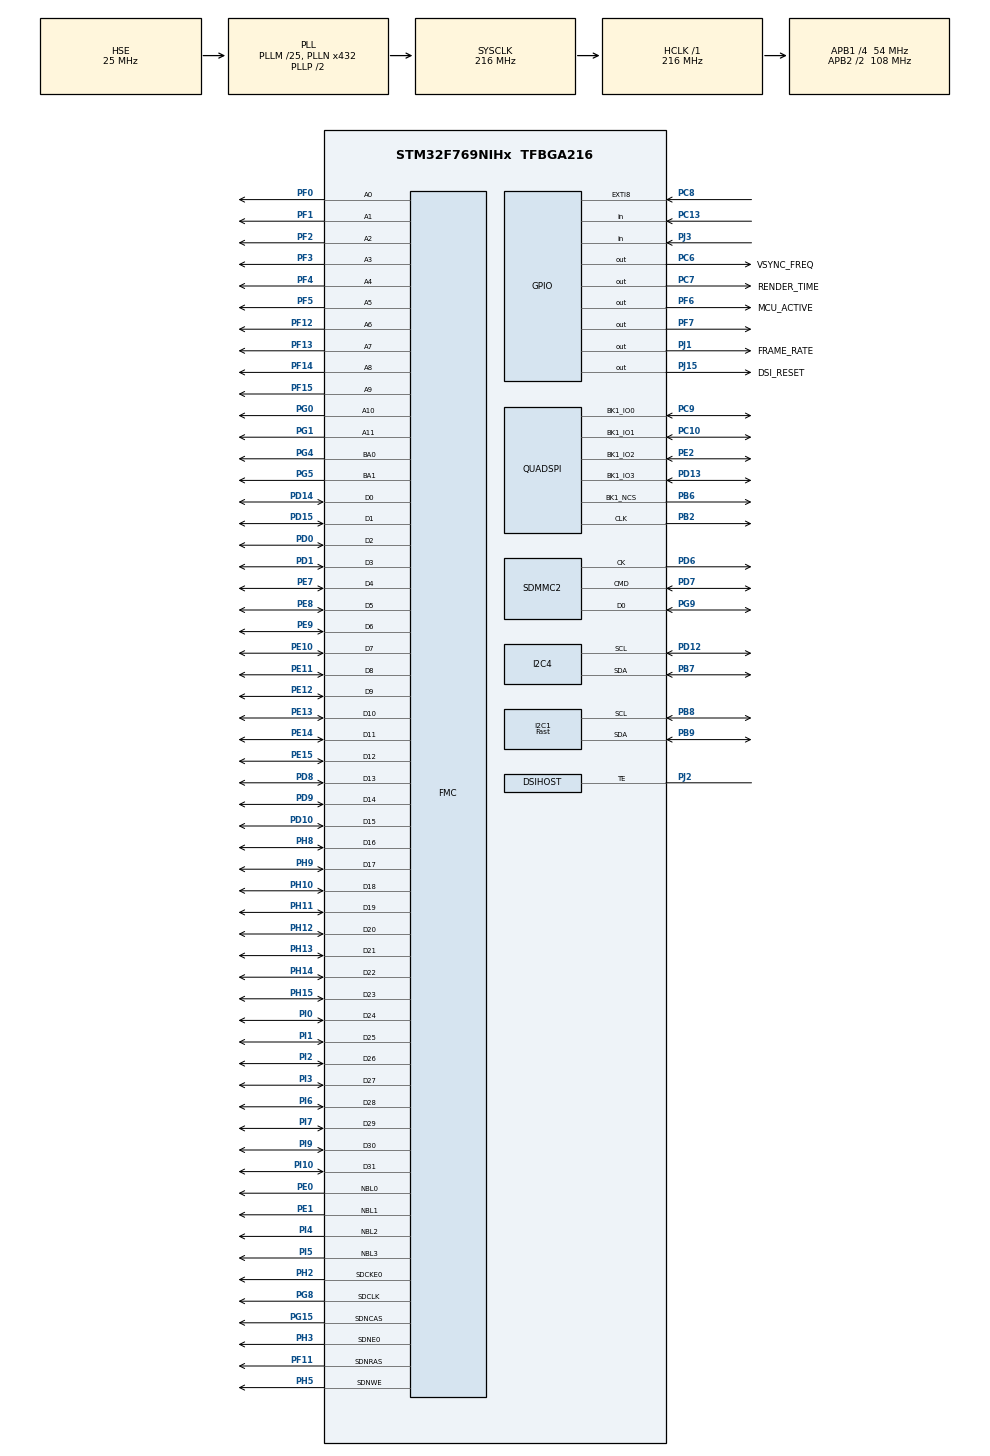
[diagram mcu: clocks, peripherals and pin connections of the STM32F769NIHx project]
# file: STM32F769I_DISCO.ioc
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CORTEX_M7.ART_ACCLERATOR_ENABLE=1
CORTEX_M7.AccessPermission-Cortex_Memory_Protection_Unit_Region0_Settings=MPU_REGION_FULL_ACCESS
CORTEX_M7.AccessPermission-Cortex_Memory_Protection_Unit_Region1_Settings=MPU_REGION_NO_ACCESS
CORTEX_M7.AccessPermission-Cortex_Memory_Protection_Unit_Region2_Settings=MPU_REGION_FULL_ACCESS
CORTEX_M7.AccessPermission-Cortex_Memory_Protection_Unit_Region3_Settings=MPU_REGION_NO_ACCESS
CORTEX_M7.AccessPermission-Cortex_Memory_Protection_Unit_Region4_Settings=MPU_REGION_FULL_ACCESS
CORTEX_M7.BaseAddress-Cortex_Memory_Protection_Unit_Region0_Settings=0x20000000
CORTEX_M7.BaseAddress-Cortex_Memory_Protection_Unit_Region1_Settings=0x90000000
CORTEX_M7.BaseAddress-Cortex_Memory_Protection_Unit_Region2_Settings=0x90000000
CORTEX_M7.BaseAddress-Cortex_Memory_Protection_Unit_Region3_Settings=0xC0000000
CORTEX_M7.BaseAddress-Cortex_Memory_Protection_Unit_Region4_Settings=0xC0000000
CORTEX_M7.CPU_DCache=Enabled
CORTEX_M7.CPU_ICache=Disabled
CORTEX_M7.DisableExec-Cortex_Memory_Protection_Unit_Region0_Settings=MPU_INSTRUCTION_ACCESS_DISABLE
CORTEX_M7.DisableExec-Cortex_Memory_Protection_Unit_Region1_Settings=MPU_INSTRUCTION_ACCESS_DISABLE
CORTEX_M7.DisableExec-Cortex_Memory_Protection_Unit_Region2_Settings=MPU_INSTRUCTION_ACCESS_DISABLE
CORTEX_M7.DisableExec-Cortex_Memory_Protection_Unit_Region3_Settings=MPU_INSTRUCTION_ACCESS_DISABLE
CORTEX_M7.DisableExec-Cortex_Memory_Protection_Unit_Region4_Settings=MPU_INSTRUCTION_ACCESS_DISABLE
CORTEX_M7.Enable-Cortex_Memory_Protection_Unit_Region0_Settings=MPU_REGION_ENABLE
CORTEX_M7.Enable-Cortex_Memory_Protection_Unit_Region1_Settings=MPU_REGION_ENABLE
CORTEX_M7.Enable-Cortex_Memory_Protection_Unit_Region2_Settings=MPU_REGION_ENABLE
CORTEX_M7.Enable-Cortex_Memory_Protection_Unit_Region3_Settings=MPU_REGION_ENABLE
CORTEX_M7.Enable-Cortex_Memory_Protection_Unit_Region4_Settings=MPU_REGION_ENABLE
CORTEX_M7.IsBufferable-Cortex_Memory_Protection_Unit_Region0_Settings=MPU_ACCESS_BUFFERABLE
CORTEX_M7.IsBufferable-Cortex_Memory_Protection_Unit_Region2_Settings=MPU_ACCESS_BUFFERABLE
CORTEX_M7.IsBufferable-Cortex_Memory_Protection_Unit_Region3_Settings=MPU_ACCESS_NOT_BUFFERABLE
CORTEX_M7.IsBufferable-Cortex_Memory_Protection_Unit_Region4_Settings=MPU_ACCESS_BUFFERABLE
CORTEX_M7.IsCacheable-Cortex_Memory_Protection_Unit_Region0_Settings=MPU_ACCESS_CACHEABLE
CORTEX_M7.IsCacheable-Cortex_Memory_Protection_Unit_Region2_Settings=MPU_ACCESS_CACHEABLE
CORTEX_M7.IsCacheable-Cortex_Memory_Protection_Unit_Region3_Settings=MPU_ACCESS_NOT_CACHEABLE
CORTEX_M7.IsCacheable-Cortex_Memory_Protection_Unit_Region4_Settings=MPU_ACCESS_CACHEABLE
CORTEX_M7.IsShareable-Cortex_Memory_Protection_Unit_Region0_Settings=MPU_ACCESS_NOT_SHAREABLE
CORTEX_M7.IsShareable-Cortex_Memory_Protection_Unit_Region2_Settings=MPU_ACCESS_NOT_SHAREABLE
CORTEX_M7.MPU_Control=MPU_PRIVILEGED_DEFAULT
CORTEX_M7.PREFETCH_ENABLE=0
CORTEX_M7.Size-Cortex_Memory_Protection_Unit_Region0_Settings=MPU_REGION_SIZE_512KB
CORTEX_M7.Size-Cortex_Memory_Protection_Unit_Region1_Settings=MPU_REGION_SIZE_512MB
CORTEX_M7.Size-Cortex_Memory_Protection_Unit_Region2_Settings=MPU_REGION_SIZE_64MB
CORTEX_M7.Size-Cortex_Memory_Protection_Unit_Region3_Settings=MPU_REGION_SIZE_512MB
CORTEX_M7.Size-Cortex_Memory_Protection_Unit_Region4_Settings=MPU_REGION_SIZE_16MB
DMA2D.ColorMode=DMA2D_OUTPUT_ARGB8888
DMA2D.Mode=DMA2D_M2M
DSIHOST.AcknowledgeRequest=DSI_ACKNOWLEDGE_ENABLE
DSIHOST.AutomaticRefresh=DSI_AR_DISABLE
DSIHOST.BTA_FlowControl=DSI_FLOW_CONTROL_BTA
DSIHOST.CommandSize=200
DSIHOST.LPDcsLongWrite=DSI_LP_DLW_ENABLE
DSIHOST.LPDcsShortReadNoP=DSI_LP_DSR0P_ENABLE
DSIHOST.LPDcsShortWriteNoP=DSI_LP_DSW0P_ENABLE
DSIHOST.LPDcsShortWriteOneP=DSI_LP_DSW1P_ENABLE
DSIHOST.LPGenLongWrite=DSI_LP_GLW_ENABLE
DSIHOST.LPGenShortReadNoP=DSI_LP_GSR0P_ENABLE
DSIHOST.LPGenShortReadOneP=DSI_LP_GSR1P_ENABLE
DSIHOST.LPGenShortReadTwoP=DSI_LP_GSR2P_ENABLE
DSIHOST.LPGenShortWriteNoP=DSI_LP_GSW0P_ENABLE
DSIHOST.LPGenShortWriteOneP=DSI_LP_GSW1P_ENABLE
DSIHOST.LPGenShortWriteTwoP=DSI_LP_GSW2P_ENABLE
DSIHOST.LPMaxReadPacket=DSI_LP_MRDP_ENABLE
DSIHOST.LPWREIE=HAL_DSI_ERROR_OVF
DSIHOST.NumberOfLanes=DSI_TWO_DATA_LANES
DSIHOST.TEAcknowledgeRequest=DSI_TE_ACKNOWLEDGE_ENABLE
DSIHOST_CKN.Mode=DSIHost_Adapted_TE
DSIHOST_CKN.Signal=DSIHOST_CKN
DSIHOST_CKP.Mode=DSIHost_Adapted_TE
DSIHOST_CKP.Signal=DSIHOST_CKP
DSIHOST_D0N.Mode=DSIHost_Adapted_TE
DSIHOST_D0N.Signal=DSIHOST_D0N
DSIHOST_D0P.Mode=DSIHost_Adapted_TE
DSIHOST_D0P.Signal=DSIHOST_D0P
DSIHOST_D1N.Mode=DSIHost_Adapted_TE
DSIHOST_D1N.Signal=DSIHOST_D1N
DSIHOST_D1P.Mode=DSIHost_Adapted_TE
DSIHOST_D1P.Signal=DSIHOST_D1P
Dma.Request0=SDMMC2_RX
Dma.Request1=SDMMC2_TX
Dma.SDMMC2_RX.0.Direction=DMA_PERIPH_TO_MEMORY
Dma.SDMMC2_RX.0.FIFOMode=DMA_FIFOMODE_ENABLE
Dma.SDMMC2_RX.0.FIFOThreshold=DMA_FIFO_THRESHOLD_FULL
Dma.SDMMC2_RX.0.Instance=DMA2_Stream0
Dma.SDMMC2_RX.0.MemBurst=DMA_MBURST_INC4
Dma.SDMMC2_RX.0.MemDataAlignment=DMA_MDATAALIGN_WORD
Dma.SDMMC2_RX.0.MemInc=DMA_MINC_ENABLE
Dma.SDMMC2_RX.0.Mode=DMA_PFCTRL
Dma.SDMMC2_RX.0.PeriphBurst=DMA_PBURST_INC4
Dma.SDMMC2_RX.0.PeriphDataAlignment=DMA_PDATAALIGN_WORD
Dma.SDMMC2_RX.0.PeriphInc=DMA_PINC_DISABLE
Dma.SDMMC2_RX.0.Priority=DMA_PRIORITY_LOW
Dma.SDMMC2_TX.1.Direction=DMA_MEMORY_TO_PERIPH
Dma.SDMMC2_TX.1.FIFOMode=DMA_FIFOMODE_ENABLE
Dma.SDMMC2_TX.1.FIFOThreshold=DMA_FIFO_THRESHOLD_FULL
Dma.SDMMC2_TX.1.Instance=DMA2_Stream5
Dma.SDMMC2_TX.1.MemBurst=DMA_MBURST_INC4
Dma.SDMMC2_TX.1.MemDataAlignment=DMA_MDATAALIGN_WORD
Dma.SDMMC2_TX.1.MemInc=DMA_MINC_ENABLE
Dma.SDMMC2_TX.1.Mode=DMA_PFCTRL
Dma.SDMMC2_TX.1.PeriphBurst=DMA_PBURST_INC4
Dma.SDMMC2_TX.1.PeriphDataAlignment=DMA_PDATAALIGN_WORD
Dma.SDMMC2_TX.1.PeriphInc=DMA_PINC_DISABLE
Dma.SDMMC2_TX.1.Priority=DMA_PRIORITY_LOW
FATFS.BSP.number=1
FATFS._FS_EXFAT=1
FATFS._MAX_SS=4096
FATFS._USE_LFN=2
FATFS0.BSP.STBoard=false
FATFS0.BSP.api=Unknown
FATFS0.BSP.instance=PC13
FATFS0.BSP.ip=GPIO
FATFS0.BSP.mode=Input
FATFS0.BSP.name=Detect_SDIO
FATFS0.BSP.solution=PC13
FMC.CASLatency1=FMC_SDRAM_CAS_LATENCY_3
FMC.ExitSelfRefreshDelay1=7
FMC.LoadToActiveDelay1=2
FMC.RCDDelay1=3
FMC.RPDelay1=2
FMC.ReadBurst1=FMC_SDRAM_RBURST_ENABLE
FMC.RowCycleDelay1=7
FMC.SDClockPeriod1=FMC_SDRAM_CLOCK_PERIOD_2
FMC.SelfRefreshTime1=4
FMC.WriteRecoveryTime1=2
FREERTOS.Queues01=gyroYqueue,16,uint16_t,0,Dynamic,NULL,NULL;engineRPMqueue,16,uint16_t,0,Dynamic,NULL,NULL;accYqueue,16,uint16_t,0,Dynamic,NULL,NULL;accXqueue,16,uint16_t,0,Dynamic,NULL,NULL;engineTempQueue,16,uint16_t,0,Dynamic,NULL,NULL
FREERTOS.Tasks01=defaultTask,24,128,StartDefaultTask,Default,NULL,Dynamic,NULL,NULL;TouchGFXTask,24,4096,TouchGFX_Task,As external,NULL,Dynamic,NULL,NULL;videoTask,8,1000,videoTaskFunc,As external,NULL,Dynamic,NULL,NULL;mountSD,24,512,MountSDCardTask,Default,NULL,Dynamic,NULL,NULL;measureSensor,24,512,SensorDataTask,Default,NULL,Dynamic,NULL,NULL;measureTemp,40,256,StartTempTask,Default,NULL,Dynamic,NULL,NULL;measureRPM,8,256,MeasureRPMTask,Default,NULL,Dynamic,NULL,NULL;setRPMZero,8,128,SetRPMZero,Default,NULL,Dynamic,NULL,NULL
FREERTOS.configCHECK_FOR_STACK_OVERFLOW=2
FREERTOS.configLIBRARY_MAX_SYSCALL_INTERRUPT_PRIORITY=5
FREERTOS.configTOTAL_HEAP_SIZE=80000
FREERTOS.configUSE_IDLE_HOOK=1
I2C1.I2C_Speed_Mode=I2C_Fast
I2C1.Timing=0x6000030D
I2C4.Timing=0x20404768
LIBJPEG.RGB_ORDERING=BGR
LTDC.ActiveH=480
LTDC.ActiveW=200
LTDC.Alpha_L0=255
LTDC.BlendingFactor1_L0=LTDC_BLENDING_FACTOR1_CA
LTDC.BlendingFactor2_L0=LTDC_BLENDING_FACTOR2_CA
LTDC.FBStartAdress_L0=0
LTDC.HBP=1
LTDC.HFP=1
LTDC.HSync=2
LTDC.ImageHeight_L0=480
LTDC.ImageWidth_L0=200
LTDC.Layers=0
LTDC.PixelFormat_L0=LTDC_PIXEL_FORMAT_RGB565
LTDC.Red=0
LTDC.VBP=1
LTDC.VFP=1
LTDC.VSync=2
LTDC.WindowX1_L0=200
LTDC.WindowY1_L0=480
Mcu.Family=STM32F7
Mcu.Name=STM32F769NIHx
Mcu.Package=TFBGA216
NVIC.DMA2D_IRQn=true\:5\:0\:true\:false\:true\:true\:true\:true\:true
NVIC.DMA2_Stream0_IRQn=true\:5\:0\:true\:false\:true\:true\:false\:true\:true
NVIC.DMA2_Stream5_IRQn=true\:5\:0\:true\:false\:true\:true\:false\:true\:true
NVIC.DSI_IRQn=true\:5\:0\:true\:false\:true\:true\:true\:true\:true
NVIC.EXTI9_5_IRQn=true\:5\:0\:false\:false\:true\:true\:true\:true\:true
NVIC.I2C4_EV_IRQn=true\:5\:0\:false\:false\:true\:false\:true\:true\:true
NVIC.LTDC_IRQn=true\:3\:0\:true\:false\:true\:false\:true\:true\:true
NVIC.PriorityGroup=NVIC_PRIORITYGROUP_4
NVIC.SDMMC2_IRQn=true\:5\:0\:true\:false\:true\:true\:true\:true\:true
NVIC.TIM2_IRQn=true\:5\:0\:false\:false\:true\:true\:true\:true\:true
NVIC.TIM3_IRQn=true\:5\:0\:true\:false\:true\:true\:true\:true\:true
NVIC.TIM6_DAC_IRQn=true\:0\:0\:false\:false\:true\:false\:false\:true\:true
NVIC.TIM7_IRQn=true\:5\:0\:true\:false\:true\:true\:true\:true\:true
NVIC.TimeBase=TIM6_DAC_IRQn
NVIC.TimeBaseIP=TIM6
PB2.Mode=Single Bank 1
PB2.Signal=QUADSPI_CLK
PB6.GPIO_PuPd=GPIO_PULLUP
PB6.Mode=Single Bank 1
PB6.Signal=QUADSPI_BK1_NCS
PB7.GPIO_Pu=GPIO_PULLUP
PB7.Mode=I2C
PB7.Signal=I2C4_SDA
PB8.Mode=I2C
PB8.Signal=I2C1_SCL
PB9.Mode=I2C
PB9.Signal=I2C1_SDA
PC10.Mode=Single Bank 1
PC10.Signal=QUADSPI_BK1_IO1
PC13.Signal=GPIO_Input
PC6.GPIO_Label=VSYNC_FREQ
PC6.GPIO_Speed=GPIO_SPEED_FREQ_VERY_HIGH
PC6.Signal=GPIO_Output
PC7.GPIO_Label=RENDER_TIME
PC7.GPIO_Speed=GPIO_SPEED_FREQ_VERY_HIGH
PC7.Signal=GPIO_Output
PC8.GPIO_ModeDefaultEXTI=GPIO_MODE_IT_RISING
PC8.GPIO_PuPd=GPIO_PULLUP
PC8.Signal=GPXTI8
PC9.Mode=Single Bank 1
PC9.Signal=QUADSPI_BK1_IO0
PD0.Signal=FMC_D2_DA2
PD1.Signal=FMC_D3_DA3
PD10.Signal=FMC_D15_DA15
PD12.GPIO_Pu=GPIO_PULLUP
PD12.Mode=I2C
PD12.Signal=I2C4_SCL
PD13.Mode=Single Bank 1
PD13.Signal=QUADSPI_BK1_IO3
PD14.Signal=FMC_D0_DA0
PD15.Signal=FMC_D1_DA1
PD6.Mode=SD_1_bit
PD6.Signal=SDMMC2_CK
PD7.Mode=SD_1_bit
PD7.Signal=SDMMC2_CMD
PD8.Signal=FMC_D13_DA13
PD9.Signal=FMC_D14_DA14
PE0.Signal=FMC_NBL0
PE1.Signal=FMC_NBL1
PE10.Signal=FMC_D7_DA7
PE11.Signal=FMC_D8_DA8
PE12.Signal=FMC_D9_DA9
PE13.Signal=FMC_D10_DA10
PE14.Signal=FMC_D11_DA11
PE15.Signal=FMC_D12_DA12
PE2.Mode=Single Bank 1
PE2.Signal=QUADSPI_BK1_IO2
PE7.Signal=FMC_D4_DA4
PE8.Signal=FMC_D5_DA5
PE9.Signal=FMC_D6_DA6
PF0.Signal=FMC_A0
PF1.Signal=FMC_A1
PF11.Signal=FMC_SDNRAS
PF12.Signal=FMC_A6
PF13.Signal=FMC_A7
PF14.Signal=FMC_A8
PF15.Signal=FMC_A9
PF2.Signal=FMC_A2
PF3.Signal=FMC_A3
PF4.Signal=FMC_A4
PF5.Signal=FMC_A5
PF6.GPIO_Label=MCU_ACTIVE
PF6.GPIO_Speed=GPIO_SPEED_FREQ_VERY_HIGH
PF6.Signal=GPIO_Output
PF7.Signal=GPIO_Output
PG0.Signal=FMC_A10
PG1.Signal=FMC_A11
PG15.Signal=FMC_SDNCAS
PG4.Signal=FMC_A14_BA0
PG5.Signal=FMC_A15_BA1
PG8.Signal=FMC_SDCLK
PG9.Mode=SD_1_bit
PG9.Signal=SDMMC2_D0
PH0/OSC_IN.Mode=HSE-External-Oscillator
PH0/OSC_IN.Signal=RCC_OSC_IN
PH1/OSC_OUT.Mode=HSE-External-Oscillator
PH1/OSC_OUT.Signal=RCC_OSC_OUT
PH10.Signal=FMC_D18
PH11.Signal=FMC_D19
PH12.Signal=FMC_D20
PH13.Signal=FMC_D21
PH14.Signal=FMC_D22
PH15.Signal=FMC_D23
PH2.Mode=SdramChipSelect1_1
PH2.Signal=FMC_SDCKE0
PH3.Mode=SdramChipSelect1_1
PH3.Signal=FMC_SDNE0
PH5.Signal=FMC_SDNWE
PH8.Signal=FMC_D16
PH9.Signal=FMC_D17
PI0.Signal=FMC_D24
PI1.Signal=FMC_D25
PI10.Signal=FMC_D31
PI2.Signal=FMC_D26
PI3.Signal=FMC_D27
PI4.Signal=FMC_NBL2
PI5.Signal=FMC_NBL3
PI6.Signal=FMC_D28
PI7.Signal=FMC_D29
PI9.Signal=FMC_D30
PJ1.GPIO_Label=FRAME_RATE
PJ1.GPIO_Speed=GPIO_SPEED_FREQ_VERY_HIGH
PJ1.Signal=GPIO_Output
PJ15.GPIO_Label=DSI_RESET
PJ15.GPIO_PuPd=GPIO_PULLUP
PJ15.GPIO_Speed=GPIO_SPEED_FREQ_MEDIUM
PJ15.PinState=GPIO_PIN_SET
PJ15.Signal=GPIO_Output
PJ2.Mode=DSIHost_Adapted_TE
PJ2.Signal=DSIHOST_TE
PJ3.Signal=GPIO_Input
ProjectManager.HeapSize=0x2000
ProjectManager.StackSize=0x2000
ProjectManager.TargetToolchain=STM32CubeIDE
QUADSPI.ChipSelectHighTime=QSPI_CS_HIGH_TIME_4_CYCLE
QUADSPI.ClockPrescaler=1
QUADSPI.FifoThreshold=16
QUADSPI.FlashSize=25
QUADSPI.SampleShifting=QSPI_SAMPLE_SHIFTING_HALFCYCLE
RCC.AHBFreq_Value=216000000
RCC.APB1CLKDivider=RCC_HCLK_DIV4
RCC.APB1Freq_Value=54000000
RCC.APB1TimFreq_Value=108000000
RCC.APB2CLKDivider=RCC_HCLK_DIV2
RCC.APB2Freq_Value=108000000
RCC.APB2TimFreq_Value=216000000
RCC.CortexFreq_Value=216000000
RCC.HCLKFreq_Value=216000000
RCC.HSE_VALUE=25000000
RCC.HSI_VALUE=16000000
RCC.LSE_VALUE=32768
RCC.PLLDSIIDF=DSI_PLL_IN_DIV5
RCC.PLLDSINDIV=100
RCC.PLLM=25
RCC.PLLN=432
RCC.PLLQ=9
RCC.PLLR=7
RCC.PLLSAIN=384
RCC.PLLSAIR=7
RCC.PLLSourceVirtual=RCC_PLLSOURCE_HSE
RCC.SDMMC2ClockSelection=RCC_SDMMC2CLKSOURCE_CLK48
RCC.SYSCLKFreq_VALUE=216000000
RCC.SYSCLKSource=RCC_SYSCLKSOURCE_PLLCLK
RCC.USBFreq_Value=48000000
RCC.VCOOutputFreq_Value=432000000
RTC.Year=24
SH.FMC_A0.0=FMC_A0,12b-sda1
SH.FMC_A1.0=FMC_A1,12b-sda1
SH.FMC_A10.0=FMC_A10,12b-sda1
SH.FMC_A11.0=FMC_A11,12b-sda1
SH.FMC_A14_BA0.0=FMC_BA0,FourSdramBanks1
SH.FMC_A15_BA1.0=FMC_BA1,FourSdramBanks1
SH.FMC_A2.0=FMC_A2,12b-sda1
SH.FMC_A3.0=FMC_A3,12b-sda1
SH.FMC_A4.0=FMC_A4,12b-sda1
SH.FMC_A5.0=FMC_A5,12b-sda1
SH.FMC_A6.0=FMC_A6,12b-sda1
SH.FMC_A7.0=FMC_A7,12b-sda1
SH.FMC_A8.0=FMC_A8,12b-sda1
SH.FMC_A9.0=FMC_A9,12b-sda1
SH.FMC_D0_DA0.0=FMC_D0,sd-32b-d1
SH.FMC_D10_DA10.0=FMC_D10,sd-32b-d1
SH.FMC_D11_DA11.0=FMC_D11,sd-32b-d1
SH.FMC_D12_DA12.0=FMC_D12,sd-32b-d1
SH.FMC_D13_DA13.0=FMC_D13,sd-32b-d1
SH.FMC_D14_DA14.0=FMC_D14,sd-32b-d1
SH.FMC_D15_DA15.0=FMC_D15,sd-32b-d1
SH.FMC_D16.0=FMC_D16,sd-32b-d1
SH.FMC_D17.0=FMC_D17,sd-32b-d1
SH.FMC_D18.0=FMC_D18,sd-32b-d1
SH.FMC_D19.0=FMC_D19,sd-32b-d1
SH.FMC_D1_DA1.0=FMC_D1,sd-32b-d1
SH.FMC_D20.0=FMC_D20,sd-32b-d1
SH.FMC_D21.0=FMC_D21,sd-32b-d1
SH.FMC_D22.0=FMC_D22,sd-32b-d1
SH.FMC_D23.0=FMC_D23,sd-32b-d1
SH.FMC_D24.0=FMC_D24,sd-32b-d1
SH.FMC_D25.0=FMC_D25,sd-32b-d1
SH.FMC_D26.0=FMC_D26,sd-32b-d1
SH.FMC_D27.0=FMC_D27,sd-32b-d1
SH.FMC_D28.0=FMC_D28,sd-32b-d1
SH.FMC_D29.0=FMC_D29,sd-32b-d1
SH.FMC_D2_DA2.0=FMC_D2,sd-32b-d1
SH.FMC_D30.0=FMC_D30,sd-32b-d1
SH.FMC_D31.0=FMC_D31,sd-32b-d1
SH.FMC_D3_DA3.0=FMC_D3,sd-32b-d1
SH.FMC_D4_DA4.0=FMC_D4,sd-32b-d1
SH.FMC_D5_DA5.0=FMC_D5,sd-32b-d1
SH.FMC_D6_DA6.0=FMC_D6,sd-32b-d1
SH.FMC_D7_DA7.0=FMC_D7,sd-32b-d1
SH.FMC_D8_DA8.0=FMC_D8,sd-32b-d1
SH.FMC_D9_DA9.0=FMC_D9,sd-32b-d1
SH.FMC_NBL0.0=FMC_NBL0,Sd4ByteEnable1
SH.FMC_NBL1.0=FMC_NBL1,Sd4ByteEnable1
SH.FMC_NBL2.0=FMC_NBL2,Sd4ByteEnable1
SH.FMC_NBL3.0=FMC_NBL3,Sd4ByteEnable1
SH.FMC_SDCLK.0=FMC_SDCLK,12b-sda1
SH.FMC_SDNCAS.0=FMC_SDNCAS,12b-sda1
SH.FMC_SDNRAS.0=FMC_SDNRAS,12b-sda1
SH.FMC_SDNWE.0=FMC_SDNWE,12b-sda1
STMicroelectronics.X-CUBE-TOUCHGFX.4.24.0.ApplicationCcGraphicsJjApplication=TouchGFXOoGenerator
STMicroelectronics.X-CUBE-TOUCHGFX.4.24.0.tgfx_address1=0xC0000000
STMicroelectronics.X-CUBE-TOUCHGFX.4.24.0.tgfx_address2=0xC011A000
STMicroelectronics.X-CUBE-TOUCHGFX.4.24.0.tgfx_buffering_strategy=Double
STMicroelectronics.X-CUBE-TOUCHGFX.4.24.0.tgfx_custom_height=480
STMicroelectronics.X-CUBE-TOUCHGFX.4.24.0.tgfx_custom_width=800
STMicroelectronics.X-CUBE-TOUCHGFX.4.24.0.tgfx_hardware_accelerator=dma_2d
STMicroelectronics.X-CUBE-TOUCHGFX.4.24.0.tgfx_location=Allocate
STMicroelectronics.X-CUBE-TOUCHGFX.4.24.0.tgfx_pixel_format=RGB565\:16
STMicroelectronics.X-CUBE-TOUCHGFX.4.24.0.tgfx_vector_fonts=Enabled
STMicroelectronics.X-CUBE-TOUCHGFX.4.24.0.tgfx_vector_rendering=Software
STMicroelectronics.X-CUBE-TOUCHGFX.4.24.0.tgfx_video=Software
STMicroelectronics.X-CUBE-TOUCHGFX.4.24.0.tgfx_video_height=480
STMicroelectronics.X-CUBE-TOUCHGFX.4.24.0.tgfx_video_strategy=1
STMicroelectronics.X-CUBE-TOUCHGFX.4.24.0.tgfx_video_width=800
TIM2.Period=1000000
TIM2.Prescaler=108-1
TIM3.Period=20
TIM3.Prescaler=54000-1
TIM7.Prescaler=108-1
VP_CRC_VS_CRC.Mode=CRC_Activate
VP_DMA2D_VS_DMA2D.Mode=DMA2D_Activate
VP_FATFS_VS_SDIO.Mode=SDIO
VP_FREERTOS_VS_CMSIS_V2.Mode=CMSIS_V2
VP_LIBJPEG_VS_JPEGLIB.Mode=Enabled
VP_LTDC_DSIMode.Mode=RGB565
VP_RTC_VS_RTC_Activate.Mode=RTC_Enabled
VP_RTC_VS_RTC_Calendar.Mode=RTC_Calendar
VP_STMicroelectronics.X-CUBE-TOUCHGFX_VS_GraphicsJjApplication_4.24.0.Mode=GraphicsJjApplication
VP_SYS_VS_tim6.Mode=TIM6
VP_TIM2_VS_ClockSourceINT.Mode=Internal
VP_TIM3_VS_ClockSourceINT.Mode=Internal
VP_TIM7_VS_ClockSourceINT.Mode=Enable_Timer
board=custom

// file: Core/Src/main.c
/* USER CODE BEGIN Header */
/**
  ******************************************************************************
  * @file           : main.c
  * @brief          : Main program body
  ******************************************************************************
  * @attention
  *
  * <h2><center>&copy; Copyright (c) 2020 STMicroelectronics.
  * All rights reserved.</center></h2>
  *
  * This software component is licensed by ST under BSD 3-Clause license,
  * the "License"; You may not use this file except in compliance with the
  * License. You may obtain a copy of the License at:
  *                        opensource.org/licenses/BSD-3-Clause
  *
  ******************************************************************************
  */
/* USER CODE END Header */
#include "main.h"
#include "cmsis_os.h"
#include "fatfs.h"
#include "libjpeg.h"
#include "app_touchgfx.h"

/* USER CODE BEGIN Includes */
#include "../mx25l512/mx25l512.h"
#include "../otm8009a/otm8009a.h"
#include "ds18b20.h"
#include "MPU6050.h"
#include <string.h>
#include <stdio.h>
#include <stdbool.h>
#include <stdlib.h>
#include <math.h>
/* USER CODE END Includes */

/* USER CODE BEGIN PD */

#define REFRESH_COUNT        1834
#define SDRAM_TIMEOUT                            ((uint32_t)0xFFFF)
#define SDRAM_MODEREG_BURST_LENGTH_1             ((uint16_t)0x0000)
#define SDRAM_MODEREG_BURST_LENGTH_2             ((uint16_t)0x0001)
#define SDRAM_MODEREG_BURST_LENGTH_4             ((uint16_t)0x0002)
#define SDRAM_MODEREG_BURST_LENGTH_8             ((uint16_t)0x0004)
#define SDRAM_MODEREG_BURST_TYPE_SEQUENTIAL      ((uint16_t)0x0000)
#define SDRAM_MODEREG_BURST_TYPE_INTERLEAVED     ((uint16_t)0x0008)
#define SDRAM_MODEREG_CAS_LATENCY_2              ((uint16_t)0x0020)
#define SDRAM_MODEREG_CAS_LATENCY_3              ((uint16_t)0x0030)
#define SDRAM_MODEREG_OPERATING_MODE_STANDARD    ((uint16_t)0x0000)
#define SDRAM_MODEREG_WRITEBURST_MODE_PROGRAMMED ((uint16_t)0x0000)
#define SDRAM_MODEREG_WRITEBURST_MODE_SINGLE     ((uint16_t)0x0200)

/* QSPI Error codes */
#define QSPI_OK            ((uint8_t)0x00)
#define QSPI_ERROR         ((uint8_t)0x01)
#define QSPI_BUSY          ((uint8_t)0x02)
#define QSPI_NOT_SUPPORTED ((uint8_t)0x04)
#define QSPI_SUSPENDED     ((uint8_t)0x08)

/* DISPLAY */
#define LCD_ORIENTATION_LANDSCAPE 0x01

#define DISPLAY_WIDTH  800   // Width of the display
#define DISPLAY_HEIGHT 472   // Height of the display
#define BAR_WIDTH      720   // Width of the bar
#define BAR_HEIGHT      20   // Height of the bar
#define BAR_SPACING     40   // Spacing between bars
#define BAR_ORIGIN_Y    50   // Y coordinate of the first bar's origin
#define MARKER_WIDTH     2   // Width of the middle marker
/* USER CODE END PD */

CRC_HandleTypeDef hcrc;

DMA2D_HandleTypeDef hdma2d;

DSI_HandleTypeDef hdsi;

I2C_HandleTypeDef hi2c1;
I2C_HandleTypeDef hi2c4;

LTDC_HandleTypeDef hltdc;

QSPI_HandleTypeDef hqspi;

RTC_HandleTypeDef hrtc;

SD_HandleTypeDef hsd2;
DMA_HandleTypeDef hdma_sdmmc2_rx;
DMA_HandleTypeDef hdma_sdmmc2_tx;

TIM_HandleTypeDef htim2;
TIM_HandleTypeDef htim3;
TIM_HandleTypeDef htim7;

SDRAM_HandleTypeDef hsdram1;

/* Definitions for defaultTask */
osThreadId_t defaultTaskHandle;
const osThreadAttr_t defaultTask_attributes = {
  .name = "defaultTask",
  .stack_size = 128 * 4,
  .priority = (osPriority_t) osPriorityNormal,
};
/* Definitions for TouchGFXTask */
osThreadId_t TouchGFXTaskHandle;
const osThreadAttr_t TouchGFXTask_attributes = {
  .name = "TouchGFXTask",
  .stack_size = 4096 * 4,
  .priority = (osPriority_t) osPriorityNormal,
};
/* Definitions for videoTask */
osThreadId_t videoTaskHandle;
const osThreadAttr_t videoTask_attributes = {
  .name = "videoTask",
  .stack_size = 1000 * 4,
  .priority = (osPriority_t) osPriorityLow,
};
/* Definitions for mountSD */
osThreadId_t mountSDHandle;
const osThreadAttr_t mountSD_attributes = {
  .name = "mountSD",
  .stack_size = 512 * 4,
  .priority = (osPriority_t) osPriorityNormal,
};
/* Definitions for measureSensor */
osThreadId_t measureSensorHandle;
const osThreadAttr_t measureSensor_attributes = {
  .name = "measureSensor",
  .stack_size = 512 * 4,
  .priority = (osPriority_t) osPriorityNormal,
};
/* Definitions for measureTemp */
osThreadId_t measureTempHandle;
const osThreadAttr_t measureTemp_attributes = {
  .name = "measureTemp",
  .stack_size = 256 * 4,
  .priority = (osPriority_t) osPriorityHigh,
};
/* Definitions for measureRPM */
osThreadId_t measureRPMHandle;
const osThreadAttr_t measureRPM_attributes = {
  .name = "measureRPM",
  .stack_size = 256 * 4,
  .priority = (osPriority_t) osPriorityLow,
};
/* Definitions for setRPMZero */
osThreadId_t setRPMZeroHandle;
const osThreadAttr_t setRPMZero_attributes = {
  .name = "setRPMZero",
  .stack_size = 128 * 4,
  .priority = (osPriority_t) osPriorityLow,
};
/* Definitions for gyroYqueue */
osMessageQueueId_t gyroYqueueHandle;
const osMessageQueueAttr_t gyroYqueue_attributes = {
  .name = "gyroYqueue"
};
/* Definitions for engineRPMqueue */
osMessageQueueId_t engineRPMqueueHandle;
const osMessageQueueAttr_t engineRPMqueue_attributes = {
  .name = "engineRPMqueue"
};
/* Definitions for accYqueue */
osMessageQueueId_t accYqueueHandle;
const osMessageQueueAttr_t accYqueue_attributes = {
  .name = "accYqueue"
};
/* Definitions for accXqueue */
osMessageQueueId_t accXqueueHandle;
const osMessageQueueAttr_t accXqueue_attributes = {
  .name = "accXqueue"
};
/* Definitions for engineTempQueue */
osMessageQueueId_t engineTempQueueHandle;
const osMessageQueueAttr_t engineTempQueue_attributes = {
  .name = "engineTempQueue"
};
/* USER CODE BEGIN PV */

DS18B20 temp_sensor;
FRESULT res; /* FatFs function common result code */
uint32_t byteswritten, bytesread; /* File write/read counts */
uint8_t wtext[WTEXT_SIZE]; /* File write buffer */
uint8_t wbuff1[BUFFER_SIZE]; /* File write buffer */
uint8_t wbuff2[BUFFER_SIZE]; /* File write buffer */
uint8_t *active_buffer = wbuff1;
uint8_t *write_buffer = wbuff2;
int activeBufferPos = 0;  // Current position in the active buffer
int writeBufferLen = 0;  // Length of the write buffer
uint8_t rtext[_MAX_SS];/* File read buffer */
char timestamp[32];
bool writeYes = false;
volatile uint16_t engineTemperature;
volatile uint32_t milliseconds = 0;
volatile uint32_t engineRpm = 0;
volatile uint32_t rpmMeasurements[3] = {0};
RTC_TimeTypeDef sTime = {0};
RTC_DateTypeDef sDate = {0};
uint8_t pcnt = 0;

/* USER CODE END PV */

void SystemClock_Config(void);
static void MPU_Config(void);
static void MX_GPIO_Init(void);
static void MX_DMA_Init(void);
static void MX_DSIHOST_DSI_Init(void);
static void MX_LTDC_Init(void);
static void MX_FMC_Init(void);
static void MX_QUADSPI_Init(void);
static void MX_DMA2D_Init(void);
static void MX_CRC_Init(void);
static void MX_SDMMC2_SD_Init(void);
static void MX_I2C1_Init(void);
static void MX_TIM3_Init(void);
static void MX_TIM7_Init(void);
static void MX_RTC_Init(void);
static void MX_TIM2_Init(void);
void StartDefaultTask(void *argument);
extern void TouchGFX_Task(void *argument);
extern void videoTaskFunc(void *argument);
void MountSDCardTask(void *argument);
void SensorDataTask(void *argument);
void StartTempTask(void *argument);
void MeasureRPMTask(void *argument);
void SetRPMZero(void *argument);

/* USER CODE BEGIN PFP */
static void BSP_SDRAM_Initialization_Sequence(SDRAM_HandleTypeDef *hsdram, FMC_SDRAM_CommandTypeDef *Command);

static uint8_t QSPI_ResetMemory(QSPI_HandleTypeDef *hqspi);
static uint8_t QSPI_EnterMemory_QPI(QSPI_HandleTypeDef *hqspi);
static uint8_t QSPI_EnterFourBytesAddress(QSPI_HandleTypeDef *hqspi);
static uint8_t QSPI_DummyCyclesCfg(QSPI_HandleTypeDef *hqspi);
static uint8_t QSPI_OutDrvStrengthCfg(QSPI_HandleTypeDef *hqspi);
static uint8_t QSPI_WriteEnable(QSPI_HandleTypeDef *hqspi);
static uint8_t QSPI_AutoPollingMemReady  (QSPI_HandleTypeDef *hqspi, uint32_t Timeout);
static uint8_t BSP_QSPI_EnableMemoryMappedMode(QSPI_HandleTypeDef *hqspi);

void GetTimestampFileString(char* timestampStr);
long map(long x, long in_min, long in_max, long out_min, long out_max);

/* USER CODE END PFP */

int main(void)
{

  /* MPU Configuration--------------------------------------------------------*/
  MPU_Config();

  /* Enable D-Cache---------------------------------------------------------*/
  SCB_EnableDCache();

  /* MCU Configuration--------------------------------------------------------*/

  /* Reset of all peripherals, Initializes the Flash interface and the Systick. */
  HAL_Init();

  /* Configure the system clock */
  SystemClock_Config();

  /* Initialize all configured peripherals */
  MX_GPIO_Init();
  MX_DMA_Init();
  MX_DSIHOST_DSI_Init();
  MX_LTDC_Init();
  MX_FMC_Init();
  MX_QUADSPI_Init();
  MX_DMA2D_Init();
  MX_I2C4_Init();
  MX_LIBJPEG_Init();
  MX_CRC_Init();
  MX_SDMMC2_SD_Init();
  MX_I2C1_Init();
  MX_TIM3_Init();
  MX_TIM7_Init();
  MX_FATFS_Init();
  MX_RTC_Init();
  MX_TIM2_Init();
  MX_TouchGFX_Init();
  /* Call PreOsInit function */
  MX_TouchGFX_PreOSInit();
  /* USER CODE BEGIN 2 */

  MPU6050_Initialization();
  DS18B20_init(&temp_sensor, &htim7, GPIOF, GPIO_PIN_7);
  GetTimestampFileString(timestamp);
  memset(wbuff1, 0, BUFFER_SIZE);
  memset(wbuff2, 0, BUFFER_SIZE);
  /* USER CODE END 2 */

  /* Init scheduler */
  osKernelInitialize();

  /* Create the queue(s) */
  /* creation of gyroYqueue */
  gyroYqueueHandle = osMessageQueueNew (16, sizeof(uint16_t), &gyroYqueue_attributes);

  /* creation of engineRPMqueue */
  engineRPMqueueHandle = osMessageQueueNew (16, sizeof(uint16_t), &engineRPMqueue_attributes);

  /* creation of accYqueue */
  accYqueueHandle = osMessageQueueNew (16, sizeof(uint16_t), &accYqueue_attributes);

  /* creation of accXqueue */
  accXqueueHandle = osMessageQueueNew (16, sizeof(uint16_t), &accXqueue_attributes);

  /* creation of engineTempQueue */
  engineTempQueueHandle = osMessageQueueNew (16, sizeof(uint16_t), &engineTempQueue_attributes);

  /* Create the thread(s) */
  /* creation of defaultTask */
  defaultTaskHandle = osThreadNew(StartDefaultTask, NULL, &defaultTask_attributes);

  /* creation of TouchGFXTask */
  TouchGFXTaskHandle = osThreadNew(TouchGFX_Task, NULL, &TouchGFXTask_attributes);

  /* creation of videoTask */
  videoTaskHandle = osThreadNew(videoTaskFunc, NULL, &videoTask_attributes);

  /* creation of mountSD */
  mountSDHandle = osThreadNew(MountSDCardTask, NULL, &mountSD_attributes);

  /* creation of measureSensor */
  measureSensorHandle = osThreadNew(SensorDataTask, NULL, &measureSensor_attributes);

  /* creation of measureTemp */
  measureTempHandle = osThreadNew(StartTempTask, NULL, &measureTemp_attributes);

  /* creation of measureRPM */
  measureRPMHandle = osThreadNew(MeasureRPMTask, NULL, &measureRPM_attributes);

  /* creation of setRPMZero */
  setRPMZeroHandle = osThreadNew(SetRPMZero, NULL, &setRPMZero_attributes);

  /* Start scheduler */
  osKernelStart();

  /* We should never get here as control is now taken by the scheduler */

  /* Infinite loop */
	while (1) {
	}

}

void SystemClock_Config(void)
{
  RCC_OscInitTypeDef RCC_OscInitStruct = {0};
  RCC_ClkInitTypeDef RCC_ClkInitStruct = {0};

  /** Configure the main internal regulator output voltage
  */
  __HAL_RCC_PWR_CLK_ENABLE();
  __HAL_PWR_VOLTAGESCALING_CONFIG(PWR_REGULATOR_VOLTAGE_SCALE1);

  /** Initializes the RCC Oscillators according to the specified parameters
  * in the RCC_OscInitTypeDef structure.
  */
  RCC_OscInitStruct.OscillatorType = RCC_OSCILLATORTYPE_LSI|RCC_OSCILLATORTYPE_HSE;
  RCC_OscInitStruct.HSEState = RCC_HSE_ON;
  RCC_OscInitStruct.LSIState = RCC_LSI_ON;
  RCC_OscInitStruct.PLL.PLLState = RCC_PLL_ON;
  RCC_OscInitStruct.PLL.PLLSource = RCC_PLLSOURCE_HSE;
  RCC_OscInitStruct.PLL.PLLM = 25;
  RCC_OscInitStruct.PLL.PLLN = 432;
  RCC_OscInitStruct.PLL.PLLP = RCC_PLLP_DIV2;
  RCC_OscInitStruct.PLL.PLLQ = 9;
  RCC_OscInitStruct.PLL.PLLR = 7;
  if (HAL_RCC_OscConfig(&RCC_OscInitStruct) != HAL_OK)
  {
    Error_Handler();
  }

  /** Activate the Over-Drive mode
  */
  if (HAL_PWREx_EnableOverDrive() != HAL_OK)
  {
    Error_Handler();
  }

  /** Initializes the CPU, AHB and APB buses clocks
  */
  RCC_ClkInitStruct.ClockType = RCC_CLOCKTYPE_HCLK|RCC_CLOCKTYPE_SYSCLK
                              |RCC_CLOCKTYPE_PCLK1|RCC_CLOCKTYPE_PCLK2;
  RCC_ClkInitStruct.SYSCLKSource = RCC_SYSCLKSOURCE_PLLCLK;
  RCC_ClkInitStruct.AHBCLKDivider = RCC_SYSCLK_DIV1;
  RCC_ClkInitStruct.APB1CLKDivider = RCC_HCLK_DIV4;
  RCC_ClkInitStruct.APB2CLKDivider = RCC_HCLK_DIV2;

  if (HAL_RCC_ClockConfig(&RCC_ClkInitStruct, FLASH_LATENCY_7) != HAL_OK)
  {
    Error_Handler();
  }
}

static void MX_CRC_Init(void)
{

  hcrc.Instance = CRC;
  hcrc.Init.DefaultPolynomialUse = DEFAULT_POLYNOMIAL_ENABLE;
  hcrc.Init.DefaultInitValueUse = DEFAULT_INIT_VALUE_ENABLE;
  hcrc.Init.InputDataInversionMode = CRC_INPUTDATA_INVERSION_NONE;
  hcrc.Init.OutputDataInversionMode = CRC_OUTPUTDATA_INVERSION_DISABLE;
  hcrc.InputDataFormat = CRC_INPUTDATA_FORMAT_BYTES;
  if (HAL_CRC_Init(&hcrc) != HAL_OK)
  {
    Error_Handler();
  }

}

static void MX_DMA2D_Init(void)
{

  hdma2d.Instance = DMA2D;
  hdma2d.Init.Mode = DMA2D_M2M;
  hdma2d.Init.ColorMode = DMA2D_OUTPUT_ARGB8888;
  hdma2d.Init.OutputOffset = 0;
  hdma2d.LayerCfg[1].InputOffset = 0;
  hdma2d.LayerCfg[1].InputColorMode = DMA2D_INPUT_ARGB8888;
  hdma2d.LayerCfg[1].AlphaMode = DMA2D_NO_MODIF_ALPHA;
  hdma2d.LayerCfg[1].InputAlpha = 0;
  hdma2d.LayerCfg[1].AlphaInverted = DMA2D_REGULAR_ALPHA;
  hdma2d.LayerCfg[1].RedBlueSwap = DMA2D_RB_REGULAR;
  if (HAL_DMA2D_Init(&hdma2d) != HAL_OK)
  {
    Error_Handler();
  }
  if (HAL_DMA2D_ConfigLayer(&hdma2d, 1) != HAL_OK)
  {
    Error_Handler();
  }

}

static void MX_DSIHOST_DSI_Init(void)
{

  /* USER CODE BEGIN DSIHOST_Init 0 */
  /* Activate XRES active low */
  HAL_GPIO_WritePin(DSI_RESET_GPIO_Port, DSI_RESET_Pin, GPIO_PIN_RESET);
  HAL_Delay(20); /* wait 20 ms */
  /* Desactivate XRES */
  HAL_GPIO_WritePin(DSI_RESET_GPIO_Port, DSI_RESET_Pin, GPIO_PIN_SET);
  /* Wait for 10ms after releasing XRES before sending commands */
  HAL_Delay(10);
  /* USER CODE END DSIHOST_Init 0 */

  DSI_PLLInitTypeDef PLLInit = {0};
  DSI_HOST_TimeoutTypeDef HostTimeouts = {0};
  DSI_PHY_TimerTypeDef PhyTimings = {0};
  DSI_LPCmdTypeDef LPCmd = {0};
  DSI_CmdCfgTypeDef CmdCfg = {0};

  hdsi.Instance = DSI;
  hdsi.Init.AutomaticClockLaneControl = DSI_AUTO_CLK_LANE_CTRL_DISABLE;
  hdsi.Init.TXEscapeCkdiv = 4;
  hdsi.Init.NumberOfLanes = DSI_TWO_DATA_LANES;
  PLLInit.PLLNDIV = 100;
  PLLInit.PLLIDF = DSI_PLL_IN_DIV5;
  PLLInit.PLLODF = DSI_PLL_OUT_DIV1;
  if (HAL_DSI_Init(&hdsi, &PLLInit) != HAL_OK)
  {
    Error_Handler();
  }
  HostTimeouts.TimeoutCkdiv = 1;
  HostTimeouts.HighSpeedTransmissionTimeout = 0;
  HostTimeouts.LowPowerReceptionTimeout = 0;
  HostTimeouts.HighSpeedReadTimeout = 0;
  HostTimeouts.LowPowerReadTimeout = 0;
  HostTimeouts.HighSpeedWriteTimeout = 0;
  HostTimeouts.HighSpeedWritePrespMode = DSI_HS_PM_DISABLE;
  HostTimeouts.LowPowerWriteTimeout = 0;
  HostTimeouts.BTATimeout = 0;
  if (HAL_DSI_ConfigHostTimeouts(&hdsi, &HostTimeouts) != HAL_OK)
  {
    Error_Handler();
  }
  PhyTimings.ClockLaneHS2LPTime = 28;
  PhyTimings.ClockLaneLP2HSTime = 33;
  PhyTimings.DataLaneHS2LPTime = 15;
  PhyTimings.DataLaneLP2HSTime = 25;
  PhyTimings.DataLaneMaxReadTime = 0;
  PhyTimings.StopWaitTime = 0;
  if (HAL_DSI_ConfigPhyTimer(&hdsi, &PhyTimings) != HAL_OK)
  {
    Error_Handler();
  }
  if (HAL_DSI_ConfigFlowControl(&hdsi, DSI_FLOW_CONTROL_BTA) != HAL_OK)
  {
    Error_Handler();
  }
  if (HAL_DSI_SetLowPowerRXFilter(&hdsi, 10000) != HAL_OK)
  {
    Error_Handler();
  }
  if (HAL_DSI_ConfigErrorMonitor(&hdsi, HAL_DSI_ERROR_OVF) != HAL_OK)
  {
    Error_Handler();
  }
  LPCmd.LPGenShortWriteNoP = DSI_LP_GSW0P_ENABLE;
  LPCmd.LPGenShortWriteOneP = DSI_LP_GSW1P_ENABLE;
  LPCmd.LPGenShortWriteTwoP = DSI_LP_GSW2P_ENABLE;
  LPCmd.LPGenShortReadNoP = DSI_LP_GSR0P_ENABLE;
  LPCmd.LPGenShortReadOneP = DSI_LP_GSR1P_ENABLE;
  LPCmd.LPGenShortReadTwoP = DSI_LP_GSR2P_ENABLE;
  LPCmd.LPGenLongWrite = DSI_LP_GLW_ENABLE;
  LPCmd.LPDcsShortWriteNoP = DSI_LP_DSW0P_ENABLE;
  LPCmd.LPDcsShortWriteOneP = DSI_LP_DSW1P_ENABLE;
  LPCmd.LPDcsShortReadNoP = DSI_LP_DSR0P_ENABLE;
  LPCmd.LPDcsLongWrite = DSI_LP_DLW_ENABLE;
  LPCmd.LPMaxReadPacket = DSI_LP_MRDP_ENABLE;
  LPCmd.AcknowledgeRequest = DSI_ACKNOWLEDGE_ENABLE;
  if (HAL_DSI_ConfigCommand(&hdsi, &LPCmd) != HAL_OK)
  {
    Error_Handler();
  }
  CmdCfg.VirtualChannelID = 0;
  CmdCfg.ColorCoding = DSI_RGB565;
  CmdCfg.CommandSize = 200;
  CmdCfg.TearingEffectSource = DSI_TE_EXTERNAL;
  CmdCfg.TearingEffectPolarity = DSI_TE_RISING_EDGE;
  CmdCfg.HSPolarity = DSI_HSYNC_ACTIVE_LOW;
  CmdCfg.VSPolarity = DSI_VSYNC_ACTIVE_LOW;
  CmdCfg.DEPolarity = DSI_DATA_ENABLE_ACTIVE_HIGH;
  CmdCfg.VSyncPol = DSI_VSYNC_FALLING;
  CmdCfg.AutomaticRefresh = DSI_AR_DISABLE;
  CmdCfg.TEAcknowledgeRequest = DSI_TE_ACKNOWLEDGE_ENABLE;
  if (HAL_DSI_ConfigAdaptedCommandMode(&hdsi, &CmdCfg) != HAL_OK)
  {
    Error_Handler();
  }
  if (HAL_DSI_SetGenericVCID(&hdsi, 0) != HAL_OK)
  {
    Error_Handler();
  }

}

static void MX_I2C1_Init(void)
{

  hi2c1.Instance = I2C1;
  hi2c1.Init.Timing = 0x6000030D;
  hi2c1.Init.OwnAddress1 = 0;
  hi2c1.Init.AddressingMode = I2C_ADDRESSINGMODE_7BIT;
  hi2c1.Init.DualAddressMode = I2C_DUALADDRESS_DISABLE;
  hi2c1.Init.OwnAddress2 = 0;
  hi2c1.Init.OwnAddress2Masks = I2C_OA2_NOMASK;
  hi2c1.Init.GeneralCallMode = I2C_GENERALCALL_DISABLE;
  hi2c1.Init.NoStretchMode = I2C_NOSTRETCH_DISABLE;
  if (HAL_I2C_Init(&hi2c1) != HAL_OK)
  {
    Error_Handler();
  }

  /** Configure Analogue filter
  */
  if (HAL_I2CEx_ConfigAnalogFilter(&hi2c1, I2C_ANALOGFILTER_ENABLE) != HAL_OK)
  {
    Error_Handler();
  }

  /** Configure Digital filter
  */
  if (HAL_I2CEx_ConfigDigitalFilter(&hi2c1, 0) != HAL_OK)
  {
    Error_Handler();
  }

}

void MX_I2C4_Init(void)
{

  hi2c4.Instance = I2C4;
  hi2c4.Init.Timing = 0x20404768;
  hi2c4.Init.OwnAddress1 = 0;
  hi2c4.Init.AddressingMode = I2C_ADDRESSINGMODE_7BIT;
  hi2c4.Init.DualAddressMode = I2C_DUALADDRESS_DISABLE;
  hi2c4.Init.OwnAddress2 = 0;
  hi2c4.Init.OwnAddress2Masks = I2C_OA2_NOMASK;
  hi2c4.Init.GeneralCallMode = I2C_GENERALCALL_DISABLE;
  hi2c4.Init.NoStretchMode = I2C_NOSTRETCH_DISABLE;
  if (HAL_I2C_Init(&hi2c4) != HAL_OK)
  {
    Error_Handler();
  }

  /** Configure Analogue filter
  */
  if (HAL_I2CEx_ConfigAnalogFilter(&hi2c4, I2C_ANALOGFILTER_ENABLE) != HAL_OK)
  {
    Error_Handler();
  }

  /** Configure Digital filter
  */
  if (HAL_I2CEx_ConfigDigitalFilter(&hi2c4, 0) != HAL_OK)
  {
    Error_Handler();
  }

}

static void MX_LTDC_Init(void)
{

  LTDC_LayerCfgTypeDef pLayerCfg = {0};

  hltdc.Instance = LTDC;
  hltdc.Init.HSPolarity = LTDC_HSPOLARITY_AL;
  hltdc.Init.VSPolarity = LTDC_VSPOLARITY_AL;
  hltdc.Init.DEPolarity = LTDC_DEPOLARITY_AL;
  hltdc.Init.PCPolarity = LTDC_PCPOLARITY_IPC;
  hltdc.Init.HorizontalSync = 1;
  hltdc.Init.VerticalSync = 1;
  hltdc.Init.AccumulatedHBP = 2;
  hltdc.Init.AccumulatedVBP = 2;
  hltdc.Init.AccumulatedActiveW = 202;
  hltdc.Init.AccumulatedActiveH = 482;
  hltdc.Init.TotalWidth = 203;
  hltdc.Init.TotalHeigh = 483;
  hltdc.Init.Backcolor.Blue = 0;
  hltdc.Init.Backcolor.Green = 0;
  hltdc.Init.Backcolor.Red = 0;
  if (HAL_LTDC_Init(&hltdc) != HAL_OK)
  {
    Error_Handler();
  }
  pLayerCfg.WindowX0 = 0;
  pLayerCfg.WindowX1 = 200;
  pLayerCfg.WindowY0 = 0;
  pLayerCfg.WindowY1 = 480;
  pLayerCfg.PixelFormat = LTDC_PIXEL_FORMAT_RGB565;
  pLayerCfg.Alpha = 255;
  pLayerCfg.Alpha0 = 0;
  pLayerCfg.BlendingFactor1 = LTDC_BLENDING_FACTOR1_CA;
  pLayerCfg.BlendingFactor2 = LTDC_BLENDING_FACTOR2_CA;
  pLayerCfg.FBStartAdress = 0;
  pLayerCfg.ImageWidth = 200;
  pLayerCfg.ImageHeight = 480;
  pLayerCfg.Backcolor.Blue = 0;
  pLayerCfg.Backcolor.Green = 0;
  pLayerCfg.Backcolor.Red = 0;
  if (HAL_LTDC_ConfigLayer(&hltdc, &pLayerCfg, 0) != HAL_OK)
  {
    Error_Handler();
  }
  /* USER CODE BEGIN LTDC_Init 2 */
  __HAL_LTDC_DISABLE(&hltdc);
  DSI_LPCmdTypeDef LPCmd;

  HAL_DSI_Start(&hdsi);
  OTM8009A_Init(OTM8009A_FORMAT_RBG565, LCD_ORIENTATION_LANDSCAPE);

  HAL_DSI_ShortWrite(&hdsi, 0, DSI_DCS_SHORT_PKT_WRITE_P1, OTM8009A_CMD_DISPOFF, 0x00);

  LPCmd.LPGenShortWriteNoP = DSI_LP_GSW0P_DISABLE;
  LPCmd.LPGenShortWriteOneP = DSI_LP_GSW1P_DISABLE;
  LPCmd.LPGenShortWriteTwoP = DSI_LP_GSW2P_DISABLE;
  LPCmd.LPGenShortReadNoP = DSI_LP_GSR0P_DISABLE;
  LPCmd.LPGenShortReadOneP = DSI_LP_GSR1P_DISABLE;
  LPCmd.LPGenShortReadTwoP = DSI_LP_GSR2P_DISABLE;
  LPCmd.LPGenLongWrite = DSI_LP_GLW_DISABLE;
  LPCmd.LPDcsShortWriteNoP = DSI_LP_DSW0P_DISABLE;
  LPCmd.LPDcsShortWriteOneP = DSI_LP_DSW1P_DISABLE;
  LPCmd.LPDcsShortReadNoP = DSI_LP_DSR0P_DISABLE;
  LPCmd.LPDcsLongWrite = DSI_LP_DLW_DISABLE;
  HAL_DSI_ConfigCommand(&hdsi, &LPCmd);

  __HAL_LTDC_ENABLE(&hltdc);

  /* USER CODE END LTDC_Init 2 */

}

static void MX_QUADSPI_Init(void)
{

  /* QUADSPI parameter configuration*/
  hqspi.Instance = QUADSPI;
  hqspi.Init.ClockPrescaler = 1;
  hqspi.Init.FifoThreshold = 16;
  hqspi.Init.SampleShifting = QSPI_SAMPLE_SHIFTING_HALFCYCLE;
  hqspi.Init.FlashSize = 25;
  hqspi.Init.ChipSelectHighTime = QSPI_CS_HIGH_TIME_4_CYCLE;
  hqspi.Init.ClockMode = QSPI_CLOCK_MODE_0;
  hqspi.Init.FlashID = QSPI_FLASH_ID_1;
  hqspi.Init.DualFlash = QSPI_DUALFLASH_DISABLE;
  if (HAL_QSPI_Init(&hqspi) != HAL_OK)
  {
    Error_Handler();
  }
  /* USER CODE BEGIN QUADSPI_Init 2 */
  /* QSPI memory reset */
  if (QSPI_ResetMemory(&hqspi) != QSPI_OK)
  {
    Error_Handler();
  }

  /* Put QSPI memory in QPI mode */
  if( QSPI_EnterMemory_QPI( &hqspi )!=QSPI_OK )
  {
    Error_Handler();
  }

  /* Set the QSPI memory in 4-bytes address mode */
  if (QSPI_EnterFourBytesAddress(&hqspi) != QSPI_OK)
  {
    Error_Handler();
  }

  /* Configuration of the dummy cycles on QSPI memory side */
  if (QSPI_DummyCyclesCfg(&hqspi) != QSPI_OK)
  {
    Error_Handler();
  }

  /* Configuration of the Output driver strength on memory side */
  if( QSPI_OutDrvStrengthCfg( &hqspi ) != QSPI_OK )
  {
    Error_Handler();
  }

  if( BSP_QSPI_EnableMemoryMappedMode(&hqspi) != QSPI_OK )
  {
    Error_Handler();
  }

  /* USER CODE END QUADSPI_Init 2 */

}

static void MX_RTC_Init(void)
{

  RTC_TimeTypeDef sTime = {0};
  RTC_DateTypeDef sDate = {0};

  /** Initialize RTC Only
  */
  hrtc.Instance = RTC;
  hrtc.Init.HourFormat = RTC_HOURFORMAT_24;
  hrtc.Init.AsynchPrediv = 127;
  hrtc.Init.SynchPrediv = 255;
  hrtc.Init.OutPut = RTC_OUTPUT_DISABLE;
  hrtc.Init.OutPutPolarity = RTC_OUTPUT_POLARITY_HIGH;
  hrtc.Init.OutPutType = RTC_OUTPUT_TYPE_OPENDRAIN;
  if (HAL_RTC_Init(&hrtc) != HAL_OK)
  {
    Error_Handler();
  }

  /** Initialize RTC and set the Time and Date
  */
  sTime.Hours = 0x0;
  sTime.Minutes = 0x0;
  sTime.Seconds = 0x0;
  sTime.DayLightSaving = RTC_DAYLIGHTSAVING_NONE;
  sTime.StoreOperation = RTC_STOREOPERATION_RESET;
  if (HAL_RTC_SetTime(&hrtc, &sTime, RTC_FORMAT_BCD) != HAL_OK)
  {
    Error_Handler();
  }
  sDate.WeekDay = RTC_WEEKDAY_MONDAY;
  sDate.Month = RTC_MONTH_JANUARY;
  sDate.Date = 0x1;
  sDate.Year = 0x24;

  if (HAL_RTC_SetDate(&hrtc, &sDate, RTC_FORMAT_BCD) != HAL_OK)
  {
    Error_Handler();
  }

}

static void MX_SDMMC2_SD_Init(void)
{

  hsd2.Instance = SDMMC2;
  hsd2.Init.ClockEdge = SDMMC_CLOCK_EDGE_RISING;
  hsd2.Init.ClockBypass = SDMMC_CLOCK_BYPASS_DISABLE;
  hsd2.Init.ClockPowerSave = SDMMC_CLOCK_POWER_SAVE_DISABLE;
  hsd2.Init.BusWide = SDMMC_BUS_WIDE_1B;
  hsd2.Init.HardwareFlowControl = SDMMC_HARDWARE_FLOW_CONTROL_DISABLE;
  hsd2.Init.ClockDiv = 0;

}

static void MX_TIM2_Init(void)
{

  TIM_ClockConfigTypeDef sClockSourceConfig = {0};
  TIM_MasterConfigTypeDef sMasterConfig = {0};

  htim2.Instance = TIM2;
  htim2.Init.Prescaler = 108-1;
  htim2.Init.CounterMode = TIM_COUNTERMODE_UP;
  htim2.Init.Period = 1000000;
  htim2.Init.ClockDivision = TIM_CLOCKDIVISION_DIV1;
  htim2.Init.AutoReloadPreload = TIM_AUTORELOAD_PRELOAD_DISABLE;
  if (HAL_TIM_Base_Init(&htim2) != HAL_OK)
  {
    Error_Handler();
  }
  sClockSourceConfig.ClockSource = TIM_CLOCKSOURCE_INTERNAL;
  if (HAL_TIM_ConfigClockSource(&htim2, &sClockSourceConfig) != HAL_OK)
  {
    Error_Handler();
  }
  sMasterConfig.MasterOutputTrigger = TIM_TRGO_RESET;
  sMasterConfig.MasterSlaveMode = TIM_MASTERSLAVEMODE_DISABLE;
  if (HAL_TIMEx_MasterConfigSynchronization(&htim2, &sMasterConfig) != HAL_OK)
  {
    Error_Handler();
  }

}

static void MX_TIM3_Init(void)
{

  TIM_ClockConfigTypeDef sClockSourceConfig = {0};
  TIM_MasterConfigTypeDef sMasterConfig = {0};

  htim3.Instance = TIM3;
  htim3.Init.Prescaler = 54000-1;
  htim3.Init.CounterMode = TIM_COUNTERMODE_UP;
  htim3.Init.Period = 20;
  htim3.Init.ClockDivision = TIM_CLOCKDIVISION_DIV1;
  htim3.Init.AutoReloadPreload = TIM_AUTORELOAD_PRELOAD_DISABLE;
  if (HAL_TIM_Base_Init(&htim3) != HAL_OK)
  {
    Error_Handler();
  }
  sClockSourceConfig.ClockSource = TIM_CLOCKSOURCE_INTERNAL;
  if (HAL_TIM_ConfigClockSource(&htim3, &sClockSourceConfig) != HAL_OK)
  {
    Error_Handler();
  }
  sMasterConfig.MasterOutputTrigger = TIM_TRGO_RESET;
  sMasterConfig.MasterSlaveMode = TIM_MASTERSLAVEMODE_DISABLE;
  if (HAL_TIMEx_MasterConfigSynchronization(&htim3, &sMasterConfig) != HAL_OK)
  {
    Error_Handler();
  }

}

static void MX_TIM7_Init(void)
{

  TIM_MasterConfigTypeDef sMasterConfig = {0};

  htim7.Instance = TIM7;
  htim7.Init.Prescaler = 108-1;
  htim7.Init.CounterMode = TIM_COUNTERMODE_UP;
  htim7.Init.Period = 65535;
  htim7.Init.AutoReloadPreload = TIM_AUTORELOAD_PRELOAD_DISABLE;
  if (HAL_TIM_Base_Init(&htim7) != HAL_OK)
  {
    Error_Handler();
  }
  sMasterConfig.MasterOutputTrigger = TIM_TRGO_RESET;
  sMasterConfig.MasterSlaveMode = TIM_MASTERSLAVEMODE_DISABLE;
  if (HAL_TIMEx_MasterConfigSynchronization(&htim7, &sMasterConfig) != HAL_OK)
  {
    Error_Handler();
  }

}

static void MX_DMA_Init(void)
{

  /* DMA controller clock enable */
  __HAL_RCC_DMA2_CLK_ENABLE();

  /* DMA interrupt init */
  /* DMA2_Stream0_IRQn interrupt configuration */
  HAL_NVIC_SetPriority(DMA2_Stream0_IRQn, 5, 0);
  HAL_NVIC_EnableIRQ(DMA2_Stream0_IRQn);
  /* DMA2_Stream5_IRQn interrupt configuration */
  HAL_NVIC_SetPriority(DMA2_Stream5_IRQn, 5, 0);
  HAL_NVIC_EnableIRQ(DMA2_Stream5_IRQn);

}

/* FMC initialization function */
static void MX_FMC_Init(void)
{

  FMC_SDRAM_TimingTypeDef SdramTiming = {0};

  /** Perform the SDRAM1 memory initialization sequence
  */
  hsdram1.Instance = FMC_SDRAM_DEVICE;
  /* hsdram1.Init */
  hsdram1.Init.SDBank = FMC_SDRAM_BANK1;
  hsdram1.Init.ColumnBitsNumber = FMC_SDRAM_COLUMN_BITS_NUM_8;
  hsdram1.Init.RowBitsNumber = FMC_SDRAM_ROW_BITS_NUM_12;
  hsdram1.Init.MemoryDataWidth = FMC_SDRAM_MEM_BUS_WIDTH_32;
  hsdram1.Init.InternalBankNumber = FMC_SDRAM_INTERN_BANKS_NUM_4;
  hsdram1.Init.CASLatency = FMC_SDRAM_CAS_LATENCY_3;
  hsdram1.Init.WriteProtection = FMC_SDRAM_WRITE_PROTECTION_DISABLE;
  hsdram1.Init.SDClockPeriod = FMC_SDRAM_CLOCK_PERIOD_2;
  hsdram1.Init.ReadBurst = FMC_SDRAM_RBURST_ENABLE;
  hsdram1.Init.ReadPipeDelay = FMC_SDRAM_RPIPE_DELAY_0;
  /* SdramTiming */
  SdramTiming.LoadToActiveDelay = 2;
  SdramTiming.ExitSelfRefreshDelay = 7;
  SdramTiming.SelfRefreshTime = 4;
  SdramTiming.RowCycleDelay = 7;
  SdramTiming.WriteRecoveryTime = 2;
  SdramTiming.RPDelay = 2;
  SdramTiming.RCDDelay = 3;

  if (HAL_SDRAM_Init(&hsdram1, &SdramTiming) != HAL_OK)
  {
    Error_Handler( );
  }

  /* USER CODE BEGIN FMC_Init 2 */

  FMC_SDRAM_CommandTypeDef command;

  /* Program the SDRAM external device */
  BSP_SDRAM_Initialization_Sequence(&hsdram1, &command);

  //Deactivate speculative/cache access to first FMC Bank to save FMC bandwidth
  FMC_Bank1->BTCR[0] = 0x000030D2;
  /* USER CODE END FMC_Init 2 */
}

static void MX_GPIO_Init(void)
{
  GPIO_InitTypeDef GPIO_InitStruct = {0};

  /* GPIO Ports Clock Enable */
  __HAL_RCC_GPIOE_CLK_ENABLE();
  __HAL_RCC_GPIOB_CLK_ENABLE();
  __HAL_RCC_GPIOD_CLK_ENABLE();
  __HAL_RCC_GPIOG_CLK_ENABLE();
  __HAL_RCC_GPIOC_CLK_ENABLE();
  __HAL_RCC_GPIOI_CLK_ENABLE();
  __HAL_RCC_GPIOF_CLK_ENABLE();
  __HAL_RCC_GPIOJ_CLK_ENABLE();
  __HAL_RCC_GPIOH_CLK_ENABLE();

  /*Configure GPIO pin Output Level */
  HAL_GPIO_WritePin(DSI_RESET_GPIO_Port, DSI_RESET_Pin, GPIO_PIN_SET);

  /*Configure GPIO pin Output Level */
  HAL_GPIO_WritePin(GPIOC, RENDER_TIME_Pin|VSYNC_FREQ_Pin, GPIO_PIN_RESET);

  /*Configure GPIO pin Output Level */
  HAL_GPIO_WritePin(GPIOF, GPIO_PIN_7|MCU_ACTIVE_Pin, GPIO_PIN_RESET);

  /*Configure GPIO pin Output Level */
  HAL_GPIO_WritePin(FRAME_RATE_GPIO_Port, FRAME_RATE_Pin, GPIO_PIN_RESET);

  /*Configure GPIO pin : PC13 */
  GPIO_InitStruct.Pin = GPIO_PIN_13;
  GPIO_InitStruct.Mode = GPIO_MODE_INPUT;
  GPIO_InitStruct.Pull = GPIO_NOPULL;
  HAL_GPIO_Init(GPIOC, &GPIO_InitStruct);

  /*Configure GPIO pin : DSI_RESET_Pin */
  GPIO_InitStruct.Pin = DSI_RESET_Pin;
  GPIO_InitStruct.Mode = GPIO_MODE_OUTPUT_PP;
  GPIO_InitStruct.Pull = GPIO_PULLUP;
  GPIO_InitStruct.Speed = GPIO_SPEED_FREQ_MEDIUM;
  HAL_GPIO_Init(DSI_RESET_GPIO_Port, &GPIO_InitStruct);

  /*Configure GPIO pin : PC8 */
  GPIO_InitStruct.Pin = GPIO_PIN_8;
  GPIO_InitStruct.Mode = GPIO_MODE_IT_RISING;
  GPIO_InitStruct.Pull = GPIO_PULLUP;
  HAL_GPIO_Init(GPIOC, &GPIO_InitStruct);

  /*Configure GPIO pins : RENDER_TIME_Pin VSYNC_FREQ_Pin */
  GPIO_InitStruct.Pin = RENDER_TIME_Pin|VSYNC_FREQ_Pin;
  GPIO_InitStruct.Mode = GPIO_MODE_OUTPUT_PP;
  GPIO_InitStruct.Pull = GPIO_NOPULL;
  GPIO_InitStruct.Speed = GPIO_SPEED_FREQ_VERY_HIGH;
  HAL_GPIO_Init(GPIOC, &GPIO_InitStruct);

  /*Configure GPIO pin : PF7 */
  GPIO_InitStruct.Pin = GPIO_PIN_7;
  GPIO_InitStruct.Mode = GPIO_MODE_OUTPUT_PP;
  GPIO_InitStruct.Pull = GPIO_NOPULL;
  GPIO_InitStruct.Speed = GPIO_SPEED_FREQ_LOW;
  HAL_GPIO_Init(GPIOF, &GPIO_InitStruct);

  /*Configure GPIO pin : MCU_ACTIVE_Pin */
  GPIO_InitStruct.Pin = MCU_ACTIVE_Pin;
  GPIO_InitStruct.Mode = GPIO_MODE_OUTPUT_PP;
  GPIO_InitStruct.Pull = GPIO_NOPULL;
  GPIO_InitStruct.Speed = GPIO_SPEED_FREQ_VERY_HIGH;
  HAL_GPIO_Init(MCU_ACTIVE_GPIO_Port, &GPIO_InitStruct);

  /*Configure GPIO pin : PJ3 */
  GPIO_InitStruct.Pin = GPIO_PIN_3;
  GPIO_InitStruct.Mode = GPIO_MODE_INPUT;
  GPIO_InitStruct.Pull = GPIO_NOPULL;
  HAL_GPIO_Init(GPIOJ, &GPIO_InitStruct);

  /*Configure GPIO pin : FRAME_RATE_Pin */
  GPIO_InitStruct.Pin = FRAME_RATE_Pin;
  GPIO_InitStruct.Mode = GPIO_MODE_OUTPUT_PP;
  GPIO_InitStruct.Pull = GPIO_NOPULL;
  GPIO_InitStruct.Speed = GPIO_SPEED_FREQ_VERY_HIGH;
  HAL_GPIO_Init(FRAME_RATE_GPIO_Port, &GPIO_InitStruct);

  /* EXTI interrupt init*/
  HAL_NVIC_SetPriority(EXTI9_5_IRQn, 5, 0);
  HAL_NVIC_EnableIRQ(EXTI9_5_IRQn);

}

/* USER CODE BEGIN 4 */
/**
  * @brief  Perform the SDRAM external memory initialization sequence
  * @param  hsdram: SDRAM handle
  * @param  Command: Pointer to SDRAM command structure
  * @retval None
  */
static void BSP_SDRAM_Initialization_Sequence(SDRAM_HandleTypeDef *hsdram, FMC_SDRAM_CommandTypeDef *Command)
{
 __IO uint32_t tmpmrd = 0;

    /* Step 1: Configure a clock configuration enable command */
    Command->CommandMode            = FMC_SDRAM_CMD_CLK_ENABLE;
    Command->CommandTarget          =  FMC_SDRAM_CMD_TARGET_BANK1;
    Command->AutoRefreshNumber      = 1;
    Command->ModeRegisterDefinition = 0;

    /* Send the command */
    HAL_SDRAM_SendCommand(hsdram, Command, SDRAM_TIMEOUT);

    /* Step 2: Insert 100 us minimum delay */
    /* Inserted delay is equal to 1 ms due to systick time base unit (ms) */
    HAL_Delay(1);

    /* Step 3: Configure a PALL (precharge all) command */
    Command->CommandMode            = FMC_SDRAM_CMD_PALL;
    Command->CommandTarget          = FMC_SDRAM_CMD_TARGET_BANK1;
    Command->AutoRefreshNumber      = 1;
    Command->ModeRegisterDefinition = 0;

    /* Send the command */
    HAL_SDRAM_SendCommand(hsdram, Command, SDRAM_TIMEOUT);

    /* Step 4: Configure an Auto Refresh command */
    Command->CommandMode            = FMC_SDRAM_CMD_AUTOREFRESH_MODE;
    Command->CommandTarget          = FMC_SDRAM_CMD_TARGET_BANK1;
    Command->AutoRefreshNumber      = 8;
    Command->ModeRegisterDefinition = 0;

    /* Send the command */
    HAL_SDRAM_SendCommand(hsdram, Command, SDRAM_TIMEOUT);

    /* Step 5: Program the external memory mode register */
    tmpmrd = (uint32_t)SDRAM_MODEREG_BURST_LENGTH_1          | \
             SDRAM_MODEREG_BURST_TYPE_SEQUENTIAL   | \
             SDRAM_MODEREG_CAS_LATENCY_3           | \
             SDRAM_MODEREG_OPERATING_MODE_STANDARD | \
             SDRAM_MODEREG_WRITEBURST_MODE_SINGLE;

    Command->CommandMode            = FMC_SDRAM_CMD_LOAD_MODE;
    Command->CommandTarget          = FMC_SDRAM_CMD_TARGET_BANK1;
    Command->AutoRefreshNumber      = 1;
    Command->ModeRegisterDefinition = tmpmrd;

    /* Send the command */
    HAL_SDRAM_SendCommand(hsdram, Command, SDRAM_TIMEOUT);

    /* Step 6: Set the refresh rate counter */
    /* Set the device refresh rate */
    HAL_SDRAM_ProgramRefreshRate(hsdram, REFRESH_COUNT);

}

/**
  * @brief  This function reset the QSPI memory.
  * @param  hqspi: QSPI handle
  * @retval None
  */
static uint8_t QSPI_ResetMemory(QSPI_HandleTypeDef *hqspi)
{
  QSPI_CommandTypeDef      s_command;
  QSPI_AutoPollingTypeDef  s_config;
  uint8_t                  reg;

  /* Send command RESET command in QPI mode (QUAD I/Os) */
  /* Initialize the reset enable command */
  s_command.InstructionMode   = QSPI_INSTRUCTION_4_LINES;
  s_command.Instruction       = RESET_ENABLE_CMD;
  s_command.AddressMode       = QSPI_ADDRESS_NONE;
  s_command.AlternateByteMode = QSPI_ALTERNATE_BYTES_NONE;
  s_command.DataMode          = QSPI_DATA_NONE;
  s_command.DummyCycles       = 0;
  s_command.DdrMode           = QSPI_DDR_MODE_DISABLE;
  s_command.DdrHoldHalfCycle  = QSPI_DDR_HHC_ANALOG_DELAY;
  s_command.SIOOMode          = QSPI_SIOO_INST_EVERY_CMD;
  /* Send the command */
  if (HAL_QSPI_Command(hqspi, &s_command, HAL_QPSI_TIMEOUT_DEFAULT_VALUE) != HAL_OK)
  {
    return QSPI_ERROR;
  }
  /* Send the reset memory command */
  s_command.Instruction = RESET_MEMORY_CMD;
  if (HAL_QSPI_Command(hqspi, &s_command, HAL_QPSI_TIMEOUT_DEFAULT_VALUE) != HAL_OK)
  {
    return QSPI_ERROR;
  }

  /* Send command RESET command in SPI mode */
  /* Initialize the reset enable command */
  s_command.InstructionMode   = QSPI_INSTRUCTION_1_LINE;
  s_command.Instruction       = RESET_ENABLE_CMD;
  /* Send the command */
  if (HAL_QSPI_Command(hqspi, &s_command, HAL_QPSI_TIMEOUT_DEFAULT_VALUE) != HAL_OK)
  {
    return QSPI_ERROR;
  }
  /* Send the reset memory command */
  s_command.Instruction = RESET_MEMORY_CMD;
  if (HAL_QSPI_Command(hqspi, &s_command, HAL_QPSI_TIMEOUT_DEFAULT_VALUE) != HAL_OK)
  {
    return QSPI_ERROR;
  }

  /* After reset CMD, 1000ms requested if QSPI memory SWReset occured during full chip erase operation */
  HAL_Delay( 1000 );

  /* Configure automatic polling mode to wait the WIP bit=0 */
  s_config.Match           = 0;
  s_config.Mask            = MX25L512_SR_WIP;
  s_config.MatchMode       = QSPI_MATCH_MODE_AND;
  s_config.StatusBytesSize = 1;
  s_config.Interval        = 0x10;
  s_config.AutomaticStop   = QSPI_AUTOMATIC_STOP_ENABLE;

  s_command.InstructionMode = QSPI_INSTRUCTION_1_LINE;
  s_command.Instruction     = READ_STATUS_REG_CMD;
  s_command.DataMode        = QSPI_DATA_1_LINE;

  if (HAL_QSPI_AutoPolling(hqspi, &s_command, &s_config, HAL_QPSI_TIMEOUT_DEFAULT_VALUE) != HAL_OK)
  {
    return QSPI_ERROR;
  }

  /* Initialize the reading of status register */
  s_command.InstructionMode   = QSPI_INSTRUCTION_1_LINE;
  s_command.Instruction       = READ_STATUS_REG_CMD;
  s_command.AddressMode       = QSPI_ADDRESS_NONE;
  s_command.AlternateByteMode = QSPI_ALTERNATE_BYTES_NONE;
  s_command.DataMode          = QSPI_DATA_1_LINE;
  s_command.DummyCycles       = 0;
  s_command.NbData            = 1;
  s_command.DdrMode           = QSPI_DDR_MODE_DISABLE;
  s_command.DdrHoldHalfCycle  = QSPI_DDR_HHC_ANALOG_DELAY;
  s_command.SIOOMode          = QSPI_SIOO_INST_EVERY_CMD;

  /* Configure the command */
  if (HAL_QSPI_Command(hqspi, &s_command, HAL_QPSI_TIMEOUT_DEFAULT_VALUE) != HAL_OK)
  {
    return QSPI_ERROR;
  }

  /* Reception of the data */
  if (HAL_QSPI_Receive(hqspi, &reg, HAL_QPSI_TIMEOUT_DEFAULT_VALUE) != HAL_OK)
  {
    return QSPI_ERROR;
  }

  /* Enable write operations, command in 1 bit */
  /* Enable write operations */
  s_command.InstructionMode   = QSPI_INSTRUCTION_1_LINE;
  s_command.Instruction       = WRITE_ENABLE_CMD;
  s_command.AddressMode       = QSPI_ADDRESS_NONE;
  s_command.AlternateByteMode = QSPI_ALTERNATE_BYTES_NONE;
  s_command.DataMode          = QSPI_DATA_NONE;
  s_command.DummyCycles       = 0;
  s_command.DdrMode           = QSPI_DDR_MODE_DISABLE;
  s_command.DdrHoldHalfCycle  = QSPI_DDR_HHC_ANALOG_DELAY;
  s_command.SIOOMode          = QSPI_SIOO_INST_EVERY_CMD;

  if (HAL_QSPI_Command(hqspi, &s_command, HAL_QPSI_TIMEOUT_DEFAULT_VALUE) != HAL_OK)
  {
    return QSPI_ERROR;
  }

  /* Configure automatic polling mode to wait for write enabling */
  s_config.Match           = MX25L512_SR_WREN;
  s_config.Mask            = MX25L512_SR_WREN;
  s_config.MatchMode       = QSPI_MATCH_MODE_AND;
  s_config.StatusBytesSize = 1;
  s_config.Interval        = 0x10;
  s_config.AutomaticStop   = QSPI_AUTOMATIC_STOP_ENABLE;

  s_command.Instruction    = READ_STATUS_REG_CMD;
  s_command.DataMode       = QSPI_DATA_1_LINE;

  if (HAL_QSPI_AutoPolling(hqspi, &s_command, &s_config, HAL_QPSI_TIMEOUT_DEFAULT_VALUE) != HAL_OK)
  {
    return QSPI_ERROR;
  }

  /* Update the configuration register with new dummy cycles */
  s_command.InstructionMode   = QSPI_INSTRUCTION_1_LINE;
  s_command.Instruction       = WRITE_STATUS_CFG_REG_CMD;
  s_command.AddressMode       = QSPI_ADDRESS_NONE;
  s_command.AlternateByteMode = QSPI_ALTERNATE_BYTES_NONE;
  s_command.DataMode          = QSPI_DATA_1_LINE;
  s_command.DummyCycles       = 0;
  s_command.NbData            = 1;
  s_command.DdrMode           = QSPI_DDR_MODE_DISABLE;
  s_command.DdrHoldHalfCycle  = QSPI_DDR_HHC_ANALOG_DELAY;
  s_command.SIOOMode          = QSPI_SIOO_INST_EVERY_CMD;

  /* Enable the Quad IO on the QSPI memory (Non-volatile bit) */
  reg |= MX25L512_SR_QUADEN;

  /* Configure the command */
  if (HAL_QSPI_Command(hqspi, &s_command, HAL_QPSI_TIMEOUT_DEFAULT_VALUE) != HAL_OK)
  {
    return QSPI_ERROR;
  }

  /* Transmission of the data */
  if (HAL_QSPI_Transmit(hqspi, &reg, HAL_QPSI_TIMEOUT_DEFAULT_VALUE) != HAL_OK)
  {
    return QSPI_ERROR;
  }

  /* 40ms  Write Status/Configuration Register Cycle Time */
  HAL_Delay( 40 );

  return QSPI_OK;
}

/**
  * @brief  This function put QSPI memory in QPI mode (quad I/O).
  * @param  hqspi: QSPI handle
  * @retval None
  */
static uint8_t QSPI_EnterMemory_QPI( QSPI_HandleTypeDef *hqspi )
{
  QSPI_CommandTypeDef      s_command;
  QSPI_AutoPollingTypeDef  s_config;

  /* Initialize the QPI enable command */
  /* QSPI memory is supported to be in SPI mode, so CMD on 1 LINE */
  s_command.InstructionMode   = QSPI_INSTRUCTION_1_LINE;
  s_command.Instruction       = ENTER_QUAD_CMD;
  s_command.AddressMode       = QSPI_ADDRESS_NONE;
  s_command.AlternateByteMode = QSPI_ALTERNATE_BYTES_NONE;
  s_command.DataMode          = QSPI_DATA_NONE;
  s_command.DummyCycles       = 0;
  s_command.DdrMode           = QSPI_DDR_MODE_DISABLE;
  s_command.DdrHoldHalfCycle  = QSPI_DDR_HHC_ANALOG_DELAY;
  s_command.SIOOMode          = QSPI_SIOO_INST_EVERY_CMD;

  /* Send the command */
  if (HAL_QSPI_Command(hqspi, &s_command, HAL_QPSI_TIMEOUT_DEFAULT_VALUE) != HAL_OK)
  {
    return QSPI_ERROR;
  }

  /* Configure automatic polling mode to wait the QUADEN bit=1 and WIP bit=0 */
  s_config.Match           = MX25L512_SR_QUADEN;
  s_config.Mask            = MX25L512_SR_QUADEN|MX25L512_SR_WIP;
  s_config.MatchMode       = QSPI_MATCH_MODE_AND;
  s_config.StatusBytesSize = 1;
  s_config.Interval        = 0x10;
  s_config.AutomaticStop   = QSPI_AUTOMATIC_STOP_ENABLE;

  s_command.InstructionMode   = QSPI_INSTRUCTION_4_LINES;
  s_command.Instruction       = READ_STATUS_REG_CMD;
  s_command.DataMode          = QSPI_DATA_4_LINES;

  if (HAL_QSPI_AutoPolling(hqspi, &s_command, &s_config, HAL_QPSI_TIMEOUT_DEFAULT_VALUE) != HAL_OK)
  {
    return QSPI_ERROR;
  }

  return QSPI_OK;
}

/**
  * @brief  This function set the QSPI memory in 4-byte address mode
  * @param  hqspi: QSPI handle
  * @retval None
  */
static uint8_t QSPI_EnterFourBytesAddress(QSPI_HandleTypeDef *hqspi)
{
  QSPI_CommandTypeDef s_command;

  /* Initialize the command */
  s_command.InstructionMode   = QSPI_INSTRUCTION_4_LINES;
  s_command.Instruction       = ENTER_4_BYTE_ADDR_MODE_CMD;
  s_command.AddressMode       = QSPI_ADDRESS_NONE;
  s_command.AlternateByteMode = QSPI_ALTERNATE_BYTES_NONE;
  s_command.DataMode          = QSPI_DATA_NONE;
  s_command.DummyCycles       = 0;
  s_command.DdrMode           = QSPI_DDR_MODE_DISABLE;
  s_command.DdrHoldHalfCycle  = QSPI_DDR_HHC_ANALOG_DELAY;
  s_command.SIOOMode          = QSPI_SIOO_INST_EVERY_CMD;

  /* Enable write operations */
  if (QSPI_WriteEnable(hqspi) != QSPI_OK)
  {
    return QSPI_ERROR;
  }

  /* Send the command */
  if (HAL_QSPI_Command(hqspi, &s_command, HAL_QPSI_TIMEOUT_DEFAULT_VALUE) != HAL_OK)
  {
    return QSPI_ERROR;
  }

  /* Configure automatic polling mode to wait the memory is ready */
  if (QSPI_AutoPollingMemReady(hqspi, HAL_QPSI_TIMEOUT_DEFAULT_VALUE) != QSPI_OK)
  {
    return QSPI_ERROR;
  }

  return QSPI_OK;
}

/**
  * @brief  This function configure the dummy cycles on memory side.
  * @param  hqspi: QSPI handle
  * @retval None
  */
static uint8_t QSPI_DummyCyclesCfg(QSPI_HandleTypeDef *hqspi)
{
  QSPI_CommandTypeDef s_command;
  uint8_t reg[2];

  /* Initialize the reading of status register */
  s_command.InstructionMode   = QSPI_INSTRUCTION_4_LINES;
  s_command.Instruction       = READ_STATUS_REG_CMD;
  s_command.AddressMode       = QSPI_ADDRESS_NONE;
  s_command.AlternateByteMode = QSPI_ALTERNATE_BYTES_NONE;
  s_command.DataMode          = QSPI_DATA_4_LINES;
  s_command.DummyCycles       = 0;
  s_command.NbData            = 1;
  s_command.DdrMode           = QSPI_DDR_MODE_DISABLE;
  s_command.DdrHoldHalfCycle  = QSPI_DDR_HHC_ANALOG_DELAY;
  s_command.SIOOMode          = QSPI_SIOO_INST_EVERY_CMD;

  /* Configure the command */
  if (HAL_QSPI_Command(hqspi, &s_command, HAL_QPSI_TIMEOUT_DEFAULT_VALUE) != HAL_OK)
  {
    return QSPI_ERROR;
  }

  /* Reception of the data */
  if (HAL_QSPI_Receive(hqspi, &(reg[0]), HAL_QPSI_TIMEOUT_DEFAULT_VALUE) != HAL_OK)
  {
    return QSPI_ERROR;
  }

  /* Initialize the reading of configuration register */
  s_command.InstructionMode   = QSPI_INSTRUCTION_4_LINES;
  s_command.Instruction       = READ_CFG_REG_CMD;
  s_command.AddressMode       = QSPI_ADDRESS_NONE;
  s_command.AlternateByteMode = QSPI_ALTERNATE_BYTES_NONE;
  s_command.DataMode          = QSPI_DATA_4_LINES;
  s_command.DummyCycles       = 0;
  s_command.NbData            = 1;
  s_command.DdrMode           = QSPI_DDR_MODE_DISABLE;
  s_command.DdrHoldHalfCycle  = QSPI_DDR_HHC_ANALOG_DELAY;
  s_command.SIOOMode          = QSPI_SIOO_INST_EVERY_CMD;

  /* Configure the command */
  if (HAL_QSPI_Command(hqspi, &s_command, HAL_QPSI_TIMEOUT_DEFAULT_VALUE) != HAL_OK)
  {
    return QSPI_ERROR;
  }

  /* Reception of the data */
  if (HAL_QSPI_Receive(hqspi, &(reg[1]), HAL_QPSI_TIMEOUT_DEFAULT_VALUE) != HAL_OK)
  {
    return QSPI_ERROR;
  }

  /* Enable write operations */
  if (QSPI_WriteEnable(hqspi) != QSPI_OK)
  {
    return QSPI_ERROR;
  }

  /* Update the configuration register with new dummy cycles */
  s_command.InstructionMode   = QSPI_INSTRUCTION_4_LINES;
  s_command.Instruction       = WRITE_STATUS_CFG_REG_CMD;
  s_command.AddressMode       = QSPI_ADDRESS_NONE;
  s_command.AlternateByteMode = QSPI_ALTERNATE_BYTES_NONE;
  s_command.DataMode          = QSPI_DATA_4_LINES;
  s_command.DummyCycles       = 0;
  s_command.NbData            = 2;
  s_command.DdrMode           = QSPI_DDR_MODE_DISABLE;
  s_command.DdrHoldHalfCycle  = QSPI_DDR_HHC_ANALOG_DELAY;
  s_command.SIOOMode          = QSPI_SIOO_INST_EVERY_CMD;

  /* MX25L512_DUMMY_CYCLES_READ_QUAD = 3 for 10 cycles in QPI mode */
  MODIFY_REG( reg[1], MX25L512_CR_NB_DUMMY, (MX25L512_DUMMY_CYCLES_READ_QUAD << POSITION_VAL(MX25L512_CR_NB_DUMMY)));

  /* Configure the write volatile configuration register command */
  if (HAL_QSPI_Command(hqspi, &s_command, HAL_QPSI_TIMEOUT_DEFAULT_VALUE) != HAL_OK)
  {
    return QSPI_ERROR;
  }

  /* Transmission of the data */
  if (HAL_QSPI_Transmit(hqspi, &(reg[0]), HAL_QPSI_TIMEOUT_DEFAULT_VALUE) != HAL_OK)
  {
    return QSPI_ERROR;
  }

  /* 40ms  Write Status/Configuration Register Cycle Time */
  HAL_Delay( 40 );

  return QSPI_OK;
}

/**
  * @brief  This function configure the Output driver strength on memory side.
  * @param  hqspi: QSPI handle
  * @retval None
  */
static uint8_t QSPI_OutDrvStrengthCfg( QSPI_HandleTypeDef *hqspi )
{
  QSPI_CommandTypeDef s_command;
  uint8_t reg[2];

  /* Initialize the reading of status register */
  s_command.InstructionMode   = QSPI_INSTRUCTION_4_LINES;
  s_command.Instruction       = READ_STATUS_REG_CMD;
  s_command.AddressMode       = QSPI_ADDRESS_NONE;
  s_command.AlternateByteMode = QSPI_ALTERNATE_BYTES_NONE;
  s_command.DataMode          = QSPI_DATA_4_LINES;
  s_command.DummyCycles       = 0;
  s_command.NbData            = 1;
  s_command.DdrMode           = QSPI_DDR_MODE_DISABLE;
  s_command.DdrHoldHalfCycle  = QSPI_DDR_HHC_ANALOG_DELAY;
  s_command.SIOOMode          = QSPI_SIOO_INST_EVERY_CMD;

  /* Configure the command */
  if (HAL_QSPI_Command(hqspi, &s_command, HAL_QPSI_TIMEOUT_DEFAULT_VALUE) != HAL_OK)
  {
    return QSPI_ERROR;
  }

  /* Reception of the data */
  if (HAL_QSPI_Receive(hqspi, &(reg[0]), HAL_QPSI_TIMEOUT_DEFAULT_VALUE) != HAL_OK)
  {
    return QSPI_ERROR;
  }

  /* Initialize the reading of configuration register */
  s_command.InstructionMode   = QSPI_INSTRUCTION_4_LINES;
  s_command.Instruction       = READ_CFG_REG_CMD;
  s_command.AddressMode       = QSPI_ADDRESS_NONE;
  s_command.AlternateByteMode = QSPI_ALTERNATE_BYTES_NONE;
  s_command.DataMode          = QSPI_DATA_4_LINES;
  s_command.DummyCycles       = 0;
  s_command.NbData            = 1;
  s_command.DdrMode           = QSPI_DDR_MODE_DISABLE;
  s_command.DdrHoldHalfCycle  = QSPI_DDR_HHC_ANALOG_DELAY;
  s_command.SIOOMode          = QSPI_SIOO_INST_EVERY_CMD;

  /* Configure the command */
  if (HAL_QSPI_Command(hqspi, &s_command, HAL_QPSI_TIMEOUT_DEFAULT_VALUE) != HAL_OK)
  {
    return QSPI_ERROR;
  }

  /* Reception of the data */
  if (HAL_QSPI_Receive(hqspi, &(reg[1]), HAL_QPSI_TIMEOUT_DEFAULT_VALUE) != HAL_OK)
  {
    return QSPI_ERROR;
  }

  /* Enable write operations */
  if (QSPI_WriteEnable(hqspi) != QSPI_OK)
  {
    return QSPI_ERROR;
  }

  /* Update the configuration register with new output driver strength */
  s_command.InstructionMode   = QSPI_INSTRUCTION_4_LINES;
  s_command.Instruction       = WRITE_STATUS_CFG_REG_CMD;
  s_command.AddressMode       = QSPI_ADDRESS_NONE;
  s_command.AlternateByteMode = QSPI_ALTERNATE_BYTES_NONE;
  s_command.DataMode          = QSPI_DATA_4_LINES;
  s_command.DummyCycles       = 0;
  s_command.NbData            = 2;
  s_command.DdrMode           = QSPI_DDR_MODE_DISABLE;
  s_command.DdrHoldHalfCycle  = QSPI_DDR_HHC_ANALOG_DELAY;
  s_command.SIOOMode          = QSPI_SIOO_INST_EVERY_CMD;

  /* Set Output Strength of the QSPI memory 15 ohms */
  MODIFY_REG( reg[1], MX25L512_CR_ODS, (MX25L512_CR_ODS_15 << POSITION_VAL(MX25L512_CR_ODS)));

  /* Configure the write volatile configuration register command */
  if (HAL_QSPI_Command(hqspi, &s_command, HAL_QPSI_TIMEOUT_DEFAULT_VALUE) != HAL_OK)
  {
    return QSPI_ERROR;
  }

  /* Transmission of the data */
  if (HAL_QSPI_Transmit(hqspi, &(reg[0]), HAL_QPSI_TIMEOUT_DEFAULT_VALUE) != HAL_OK)
  {
    return QSPI_ERROR;
  }

  return QSPI_OK;
}

/**
  * @brief  This function send a Write Enable and wait it is effective.
  * @param  hqspi: QSPI handle
  * @retval None
  */
static uint8_t QSPI_WriteEnable(QSPI_HandleTypeDef *hqspi)
{
  QSPI_CommandTypeDef     s_command;
  QSPI_AutoPollingTypeDef s_config;

  /* Enable write operations */
  s_command.InstructionMode   = QSPI_INSTRUCTION_4_LINES;
  s_command.Instruction       = WRITE_ENABLE_CMD;
  s_command.AddressMode       = QSPI_ADDRESS_NONE;
  s_command.AlternateByteMode = QSPI_ALTERNATE_BYTES_NONE;
  s_command.DataMode          = QSPI_DATA_NONE;
  s_command.DummyCycles       = 0;
  s_command.DdrMode           = QSPI_DDR_MODE_DISABLE;
  s_command.DdrHoldHalfCycle  = QSPI_DDR_HHC_ANALOG_DELAY;
  s_command.SIOOMode          = QSPI_SIOO_INST_EVERY_CMD;

  if (HAL_QSPI_Command(hqspi, &s_command, HAL_QPSI_TIMEOUT_DEFAULT_VALUE) != HAL_OK)
  {
    return QSPI_ERROR;
  }

  /* Configure automatic polling mode to wait for write enabling */
  s_config.Match           = MX25L512_SR_WREN;
  s_config.Mask            = MX25L512_SR_WREN;
  s_config.MatchMode       = QSPI_MATCH_MODE_AND;
  s_config.StatusBytesSize = 1;
  s_config.Interval        = 0x10;
  s_config.AutomaticStop   = QSPI_AUTOMATIC_STOP_ENABLE;

  s_command.Instruction    = READ_STATUS_REG_CMD;
  s_command.DataMode       = QSPI_DATA_4_LINES;

  if (HAL_QSPI_AutoPolling(hqspi, &s_command, &s_config, HAL_QPSI_TIMEOUT_DEFAULT_VALUE) != HAL_OK)
  {
    return QSPI_ERROR;
  }

  return QSPI_OK;
}

/**
  * @brief  This function read the SR of the memory and wait the EOP.
  * @param  hqspi: QSPI handle
  * @param  Timeout
  * @retval None
  */
static uint8_t QSPI_AutoPollingMemReady(QSPI_HandleTypeDef *hqspi, uint32_t Timeout)
{
  QSPI_CommandTypeDef     s_command;
  QSPI_AutoPollingTypeDef s_config;

  /* Configure automatic polling mode to wait for memory ready */
  s_command.InstructionMode   = QSPI_INSTRUCTION_4_LINES;
  s_command.Instruction       = READ_STATUS_REG_CMD;
  s_command.AddressMode       = QSPI_ADDRESS_NONE;
  s_command.AlternateByteMode = QSPI_ALTERNATE_BYTES_NONE;
  s_command.DataMode          = QSPI_DATA_4_LINES;
  s_command.DummyCycles       = 0;
  s_command.DdrMode           = QSPI_DDR_MODE_DISABLE;
  s_command.DdrHoldHalfCycle  = QSPI_DDR_HHC_ANALOG_DELAY;
  s_command.SIOOMode          = QSPI_SIOO_INST_EVERY_CMD;

  s_config.Match           = 0;
  s_config.Mask            = MX25L512_SR_WIP;
  s_config.MatchMode       = QSPI_MATCH_MODE_AND;
  s_config.StatusBytesSize = 1;
  s_config.Interval        = 0x10;
  s_config.AutomaticStop   = QSPI_AUTOMATIC_STOP_ENABLE;

  if (HAL_QSPI_AutoPolling(hqspi, &s_command, &s_config, Timeout) != HAL_OK)
  {
    return QSPI_ERROR;
  }

  return QSPI_OK;
}

/**
  * @brief  Configure the QSPI in memory-mapped mode
  * @retval QSPI memory status
  */
static uint8_t BSP_QSPI_EnableMemoryMappedMode(QSPI_HandleTypeDef *hqspi)
{
  QSPI_CommandTypeDef      s_command;
  QSPI_MemoryMappedTypeDef s_mem_mapped_cfg;

  /* Configure the command for the read instruction */
  s_command.InstructionMode   = QSPI_INSTRUCTION_4_LINES;
  s_command.Instruction       = QPI_READ_4_BYTE_ADDR_CMD;
  s_command.AddressMode       = QSPI_ADDRESS_4_LINES;
  s_command.AddressSize       = QSPI_ADDRESS_32_BITS;
  s_command.AlternateByteMode = QSPI_ALTERNATE_BYTES_NONE;
  s_command.DataMode          = QSPI_DATA_4_LINES;
  s_command.DummyCycles       = MX25L512_DUMMY_CYCLES_READ_QUAD_IO;
  s_command.DdrMode           = QSPI_DDR_MODE_DISABLE;
  s_command.DdrHoldHalfCycle  = QSPI_DDR_HHC_ANALOG_DELAY;
  s_command.SIOOMode          = QSPI_SIOO_INST_EVERY_CMD;

  /* Configure the memory mapped mode */
  s_mem_mapped_cfg.TimeOutActivation = QSPI_TIMEOUT_COUNTER_DISABLE;
  s_mem_mapped_cfg.TimeOutPeriod     = 0;

  if (HAL_QSPI_MemoryMapped(hqspi, &s_command, &s_mem_mapped_cfg) != HAL_OK)
  {
    return QSPI_ERROR;
  }

  return QSPI_OK;
}

void GetTimestampFileString(char* timestampStr)
{
    RTC_TimeTypeDef sTime;
    RTC_DateTypeDef sDate;

    HAL_RTC_GetTime(&hrtc, &sTime, RTC_FORMAT_BIN);
    HAL_RTC_GetDate(&hrtc, &sDate, RTC_FORMAT_BIN);

    snprintf(timestampStr, 32, "%04d-%02d-%02d %02d%02d%02d.txt",
             2000 + sDate.Year, sDate.Month, sDate.Date,
             sTime.Hours, sTime.Minutes, sTime.Seconds);
}

long map(long x, long in_min, long in_max, long out_min, long out_max)
{
	return (x - in_min) * (out_max - out_min) / (in_max - in_min) + out_min;
}
/* USER CODE END 4 */

void StartDefaultTask(void *argument)
{
  /* USER CODE BEGIN 5 */
  for(;;)
  {
    osDelay(100);
  }
  /* USER CODE END 5 */
}

void MountSDCardTask(void *argument)
{
  /* USER CODE BEGIN MountSDCardTask */
	res = f_mount(&SDFatFS, (TCHAR const*) SDPath, 1);
	if (res != FR_OK) {
		Error_Handler();
	} else {
		//Open file for writing (Create)
		res = f_open(&SDFile, timestamp, FA_CREATE_ALWAYS | FA_WRITE);
		if (res != FR_OK) {
			Error_Handler();
		} else {
			f_close(&SDFile);
		}

	}

	if (HAL_TIM_Base_Start_IT(&htim3) != HAL_OK) {
		Error_Handler();
	}

	if (HAL_TIM_Base_Start_IT(&htim2) != HAL_OK) {
			Error_Handler();
	}
	vTaskDelete(NULL);

	for (;;) {
		osDelay(100);
	}

  /* USER CODE END MountSDCardTask */
}

void SensorDataTask(void *argument)
{
  /* USER CODE BEGIN SensorDataTask */

	short mappedGyroY;
	short mappedAccY;
	short mappedAccX;
  /* Infinite loop */
	for (;;) {

		ulTaskNotifyTake(pdTRUE, portMAX_DELAY);

		if (MPU6050_DataReady() == 1) {
			MPU6050_ProcessData(&MPU6050);
		}

		mappedGyroY = map(MPU6050.gyro_y_raw, -32768, 32768, -300, 300);
		mappedAccY = map(MPU6050.acc_y_raw, -32768, 32768, -300, 300);
		mappedAccX = map(MPU6050.acc_x_raw, -32768, 32768, -300, 300);

		osMessageQueuePut(gyroYqueueHandle, &mappedGyroY, 0, 0);
		osMessageQueuePut(accYqueueHandle, &mappedAccX, 0, 0);
		osMessageQueuePut(accXqueueHandle, &mappedAccY, 0, 0);

		HAL_RTC_GetTime(&hrtc, &sTime, RTC_FORMAT_BIN);
		HAL_RTC_GetDate(&hrtc, &sDate, RTC_FORMAT_BIN);

		milliseconds = ((hrtc.Init.SynchPrediv - sTime.SubSeconds) * 1000)
				/ (hrtc.Init.SynchPrediv + 1);

		int wtext_len = snprintf((char*) &wtext, WTEXT_SIZE,
				"%02u\t%02u\t%02u\t%03lu\t%d\t%d\t%d\t%d\t%d\t%d\t%d\t%d\t%lu\n",
				sTime.Hours, sTime.Minutes, sTime.Seconds, milliseconds,
				MPU6050.acc_x_raw, MPU6050.acc_y_raw, MPU6050.acc_z_raw,
				MPU6050.temperature_raw, MPU6050.gyro_x_raw, MPU6050.gyro_y_raw,
				MPU6050.gyro_z_raw, engineTemperature, engineRpm);

		if (wtext_len < 0) {
			// Handle error
			Error_Handler();
		}

		memcpy(&active_buffer[activeBufferPos], &wtext, wtext_len);
		activeBufferPos += wtext_len;
		memset(&wtext, 0, WTEXT_SIZE);

		if (writeYes) {
			res = f_open(&SDFile, timestamp, FA_OPEN_APPEND | FA_WRITE);
			if (res != FR_OK) {
				// Handle open error
				Error_Handler();
			} else {
				res = f_write(&SDFile, write_buffer, writeBufferLen,
						(UINT*) &byteswritten);
				if (res != FR_OK || byteswritten != writeBufferLen) {
					// Handle write error
					Error_Handler();
				}
			}

			// Clear the buffer after writing
			memset(write_buffer, 0, BUFFER_SIZE);
			f_close(&SDFile);
			writeYes = false;
		}
		if (writeYes) {
			Error_Handler();
		} else {
			uint8_t *tmpBuff = active_buffer;
			osKernelLock();  // Disable context switching
			active_buffer = write_buffer;
			write_buffer = tmpBuff;

			writeBufferLen = activeBufferPos;
			activeBufferPos = 0;
			writeYes = true;
			osKernelUnlock();  // Enable context switching
		}
	}
  /* USER CODE END SensorDataTask */
}

void StartTempTask(void *argument)
{
  /* USER CODE BEGIN StartTempTask */

    short mappedEngineTemp;
  /* Infinite loop */
  for(;;)
  {
	  ulTaskNotifyTake(pdTRUE, portMAX_DELAY);
      engineTemperature = DS18B20_read_temp(&temp_sensor);
      mappedEngineTemp = map(engineTemperature, 0, 1920/*(120*16)*/, 0, 600);
      osMessageQueuePut(engineTempQueueHandle, &mappedEngineTemp, 0, 0);
  }
  /* USER CODE END StartTempTask */
}

void MeasureRPMTask(void *argument)
{
  /* USER CODE BEGIN MeasureRPMTask */
	short mappedEngineRPM;
	volatile uint8_t rpmIndex = 0;
	/* Infinite loop */
  for(;;)
  {
	ulTaskNotifyTake(pdTRUE, portMAX_DELAY);
	uint32_t currentTimestamp = __HAL_TIM_GET_COUNTER(&htim2);
    __HAL_TIM_SET_COUNTER(&htim2, 0);

	if(currentTimestamp > 4096)
	{

		uint32_t curr_rpm  = (60 * 200000 /*(1000000 /5)*/) / currentTimestamp;
		rpmMeasurements[rpmIndex] = curr_rpm;
		rpmIndex++;
		rpmIndex = rpmIndex%3;
		engineRpm = 0;
		for(uint8_t  i=0; i<3; i++)
		{
			engineRpm+=rpmMeasurements[i];
		}
		mappedEngineRPM = map(engineRpm, 0, 8096, 0, 600);
		osMessageQueuePut(engineRPMqueueHandle, &mappedEngineRPM, 0, 0);
	}

  }
  /* USER CODE END MeasureRPMTask */
}

void SetRPMZero(void *argument)
{
  /* USER CODE BEGIN SetRPMZero */
	short zeroVal = 0;
	/* Infinite loop */
	for (;;) {
		ulTaskNotifyTake(pdTRUE, portMAX_DELAY);
		for (uint8_t i = 0; i < 3; i++) {
			rpmMeasurements[i] = 0;
		}
		engineRpm = 0;
		osMessageQueuePut(engineRPMqueueHandle, &zeroVal, 0, 0);
	}
  /* USER CODE END SetRPMZero */
}

 /* MPU Configuration */

void MPU_Config(void)
{
  MPU_Region_InitTypeDef MPU_InitStruct = {0};

  /* Disables the MPU */
  HAL_MPU_Disable();

  /** Initializes and configures the Region and the memory to be protected
  */
  MPU_InitStruct.Enable = MPU_REGION_ENABLE;
  MPU_InitStruct.Number = MPU_REGION_NUMBER0;
  MPU_InitStruct.BaseAddress = 0x20000000;
  MPU_InitStruct.Size = MPU_REGION_SIZE_512KB;
  MPU_InitStruct.SubRegionDisable = 0x0;
  MPU_InitStruct.TypeExtField = MPU_TEX_LEVEL0;
  MPU_InitStruct.AccessPermission = MPU_REGION_FULL_ACCESS;
  MPU_InitStruct.DisableExec = MPU_INSTRUCTION_ACCESS_DISABLE;
  MPU_InitStruct.IsShareable = MPU_ACCESS_NOT_SHAREABLE;
  MPU_InitStruct.IsCacheable = MPU_ACCESS_CACHEABLE;
  MPU_InitStruct.IsBufferable = MPU_ACCESS_BUFFERABLE;

  HAL_MPU_ConfigRegion(&MPU_InitStruct);

  /** Initializes and configures the Region and the memory to be protected
  */
  MPU_InitStruct.Number = MPU_REGION_NUMBER1;
  MPU_InitStruct.BaseAddress = 0x90000000;
  MPU_InitStruct.Size = MPU_REGION_SIZE_512MB;
  MPU_InitStruct.AccessPermission = MPU_REGION_NO_ACCESS;
  MPU_InitStruct.IsCacheable = MPU_ACCESS_NOT_CACHEABLE;
  MPU_InitStruct.IsBufferable = MPU_ACCESS_NOT_BUFFERABLE;

  HAL_MPU_ConfigRegion(&MPU_InitStruct);

  /** Initializes and configures the Region and the memory to be protected
  */
  MPU_InitStruct.Number = MPU_REGION_NUMBER2;
  MPU_InitStruct.Size = MPU_REGION_SIZE_64MB;
  MPU_InitStruct.AccessPermission = MPU_REGION_FULL_ACCESS;
  MPU_InitStruct.IsCacheable = MPU_ACCESS_CACHEABLE;
  MPU_InitStruct.IsBufferable = MPU_ACCESS_BUFFERABLE;

  HAL_MPU_ConfigRegion(&MPU_InitStruct);

  /** Initializes and configures the Region and the memory to be protected
  */
  MPU_InitStruct.Number = MPU_REGION_NUMBER3;
  MPU_InitStruct.BaseAddress = 0xC0000000;
  MPU_InitStruct.Size = MPU_REGION_SIZE_512MB;
  MPU_InitStruct.AccessPermission = MPU_REGION_NO_ACCESS;
  MPU_InitStruct.IsCacheable = MPU_ACCESS_NOT_CACHEABLE;
  MPU_InitStruct.IsBufferable = MPU_ACCESS_NOT_BUFFERABLE;

  HAL_MPU_ConfigRegion(&MPU_InitStruct);

  /** Initializes and configures the Region and the memory to be protected
  */
  MPU_InitStruct.Number = MPU_REGION_NUMBER4;
  MPU_InitStruct.Size = MPU_REGION_SIZE_16MB;
  MPU_InitStruct.AccessPermission = MPU_REGION_FULL_ACCESS;
  MPU_InitStruct.IsCacheable = MPU_ACCESS_CACHEABLE;
  MPU_InitStruct.IsBufferable = MPU_ACCESS_BUFFERABLE;

  HAL_MPU_ConfigRegion(&MPU_InitStruct);
  /* Enables the MPU */
  HAL_MPU_Enable(MPU_PRIVILEGED_DEFAULT);

}

void HAL_TIM_PeriodElapsedCallback(TIM_HandleTypeDef *htim)
{
  if (htim->Instance == TIM6) {
    HAL_IncTick();
  }
}

void Error_Handler(void)
{
  /* USER CODE BEGIN Error_Handler_Debug */
  /* User can add his own implementation to report the HAL error return state */
	 vTaskEndScheduler();
  /* USER CODE END Error_Handler_Debug */
}

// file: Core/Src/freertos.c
/* USER CODE BEGIN Header */
/**
  ******************************************************************************
  * File Name          : freertos.c
  * Description        : Code for freertos applications
  ******************************************************************************
  * @attention
  *
  * <h2><center>&copy; Copyright (c) 2020 STMicroelectronics.
  * All rights reserved.</center></h2>
  *
  * This software component is licensed by ST under Ultimate Liberty license
  * SLA0044, the "License"; You may not use this file except in compliance with
  * the License. You may obtain a copy of the License at:
  *                             www.st.com/SLA0044
  *
  ******************************************************************************
  */
/* USER CODE END Header */

#include "FreeRTOS.h"
#include "task.h"
#include "main.h"

/* USER CODE BEGIN FunctionPrototypes */
   extern portBASE_TYPE IdleTaskHook(void* p);
/* USER CODE END FunctionPrototypes */

/* Hook prototypes */
void vApplicationIdleHook(void);
void vApplicationStackOverflowHook(xTaskHandle xTask, signed char *pcTaskName);

/* USER CODE BEGIN 2 */
void vApplicationIdleHook( void )
{
   /* vApplicationIdleHook() will only be called if configUSE_IDLE_HOOK is set
   to 1 in FreeRTOSConfig.h. It will be called on each iteration of the idle
   task. It is essential that code added to this hook function never attempts
   to block in any way (for example, call xQueueReceive() with a block time
   specified, or call vTaskDelay()). If the application makes use of the
   vTaskDelete() API function (as this demo application does) then it is also
   important that vApplicationIdleHook() is permitted to return to its calling
   function, because it is the responsibility of the idle task to clean up
   memory allocated by the kernel to any task that has since been deleted. */

  vTaskSetApplicationTaskTag(NULL, IdleTaskHook);
}
/* USER CODE END 2 */

/* USER CODE BEGIN 4 */
void vApplicationStackOverflowHook(xTaskHandle xTask, signed char *pcTaskName)
{
   /* Run time stack overflow checking is performed if
   configCHECK_FOR_STACK_OVERFLOW is defined to 1 or 2. This hook function is
   called if a stack overflow is detected. */
}
/* USER CODE END 4 */
